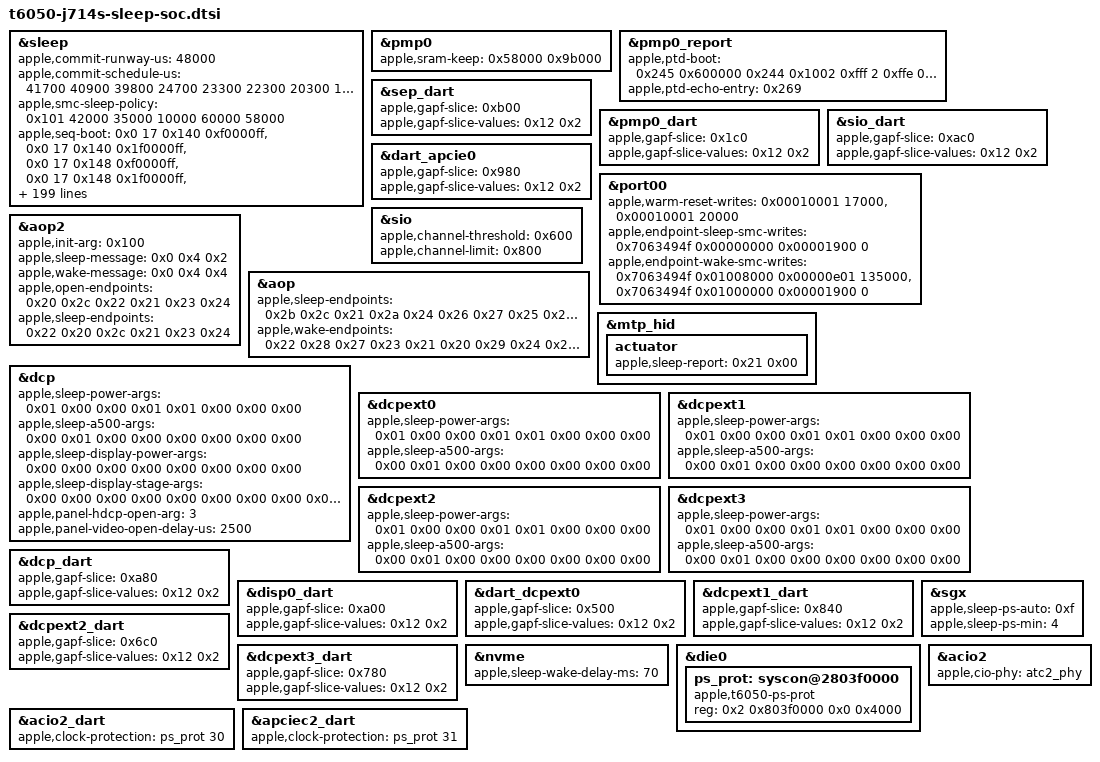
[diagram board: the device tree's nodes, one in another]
// SPDX-License-Identifier: GPL-2.0+ OR MIT
/*
 * The J714s's (MacBook Pro 14-inch, M5 Pro) SoC values for the deep sleep that the drivers take
 * from the DT, until the boot loader hands them over.
 */

&sleep {

	/* The commit window's schedule, in us before the sleep timer, step by step */
	/* The commit window: from the SMC's idle notice to the timer */
	apple,commit-runway-us = <48000>;
	apple,commit-schedule-us = <41700 40900 39800 24700 23300 22300 20300 18010 18000
		2491 2296 2202 1552 1468 1382 950 730 650 550 500>;
	/* pmVC, then the spacings: warning to pmVC, pmVC to SLPA, SLPA to idle, idle to timer, wake to pmVC */
	apple,smc-sleep-policy = <0x101 42000 35000 10000 60000 58000>;
	/* Boot: the power words put on auto, SPI_P and ATC3_USB_AON on, the SPMI masks */
	apple,seq-boot =
		<0x0 17 0x140 0xf0000ff>,
		<0x0 17 0x140 0x1f0000ff>,
		<0x0 17 0x148 0xf0000ff>,
		<0x0 17 0x148 0x1f0000ff>,
		<0x0 16 0x110 0xf0000ff>,
		<0x0 16 0x110 0x1f0000ff>,
		<0x0 16 0x168 0xf0000ff>,
		<0x0 16 0x168 0x1f0000ff>,
		<0x0 16 0x178 0xf0000ff>,
		<0x0 16 0x178 0x1f0000ff>,
		<0x0 16 0x450 0xf0000ff>,
		<0x0 16 0x450 0x1f0000ff>,
		<0x0 20 0x198 0xf0000ff>,
		<0x0 20 0x198 0x1f0000ff>,
		<0x0 20 0x130 0xf0000ff>,
		<0x0 20 0x130 0x1f0000ff>,
		<0x0 20 0x140 0xf0000ff>,
		<0x0 20 0x140 0x1f0000ff>,
		<0x0 18 0x60 0xf0000ff>,
		<0x0 18 0x60 0x1f0000ff>,
		<0x0 18 0x68 0xf0000ff>,
		<0x0 18 0x68 0x1f0000ff>,
		<0x0 18 0x128 0xf0000ff>,
		<0x0 18 0x128 0x1f0000ff>,
		<0x0 18 0x140 0xf0000ff>,
		<0x0 18 0x140 0x1f0000ff>,
		<0x0 18 0x58 0xf0000ff>,
		<0x0 18 0x58 0x1f0000ff>,
		<0x0 21 0x58 0xf0000ff>,
		<0x0 21 0x58 0x1f0000ff>,
		<0x0 16 0x148 0xf0000ff>,
		<0x0 16 0x148 0x1f0000ff>,
		<0x0 16 0x150 0xf0000ff>,
		<0x0 16 0x150 0x1f0000ff>,
		<0x0 16 0x158 0xf0000ff>,
		<0x0 16 0x158 0x1f0000ff>,
		<0x0 16 0x160 0xf0000ff>,
		<0x0 16 0x160 0x1f0000ff>,
		<0x0 16 0x1e8 0xf0000ff>,
		<0x0 16 0x1e8 0x1f0000ff>,
		<0x0 16 0x1f0 0xf0000ff>,
		<0x0 16 0x1f0 0x1f0000ff>,
		<0x0 17 0x138 0xf0000ff>,
		<0x0 17 0x138 0x1f0000ff>,
		<0x0 17 0x178 0xf0000ff>,
		<0x0 17 0x178 0x1f0000ff>,
		<0x0 17 0x288 0xf0000ff>,
		<0x0 17 0x288 0x1f0000ff>,
		<0x0 17 0x398 0xf0000ff>,
		<0x0 17 0x398 0x1f0000ff>,
		<0x0 20 0x1a8 0xf0000ff>,
		<0x0 20 0x1a8 0x1f0000ff>,
		<0x0 20 0x1b0 0xf0000ff>,
		<0x0 20 0x1b0 0x1f0000ff>,
		<0x0 20 0x218 0xf0000ff>,
		<0x0 20 0x218 0x1f0000ff>,
		<0x0 20 0x220 0xf0000ff>,
		<0x0 20 0x220 0x1f0000ff>,
		<0x0 20 0x228 0xf0000ff>,
		<0x0 20 0x228 0x1f0000ff>,
		<0x0 20 0x230 0xf0000ff>,
		<0x0 20 0x230 0x1f0000ff>,
		<0x0 20 0x238 0xf0000ff>,
		<0x0 20 0x238 0x1f0000ff>,
		<0x0 20 0x240 0xf0000ff>,
		<0x0 20 0x240 0x1f0000ff>,
		<0x0 20 0x288 0xf0000ff>,
		<0x0 20 0x288 0x1f0000ff>,
		<0x0 20 0x298 0xf0000ff>,
		<0x0 20 0x298 0x1f0000ff>,
		<0x0 20 0x2a0 0xf0000ff>,
		<0x0 20 0x2a0 0x1f0000ff>,
		<0x0 20 0x2a8 0xf0000ff>,
		<0x0 20 0x2a8 0x1f0000ff>,
		<0x0 20 0x2b0 0xf0000ff>,
		<0x0 20 0x2b0 0x1f0000ff>,
		<0x0 20 0x2b8 0xf0000ff>,
		<0x0 20 0x2b8 0x1f0000ff>,
		<0x0 20 0x2c0 0xf0000ff>,
		<0x0 20 0x2c0 0x1f0000ff>,
		<0x0 20 0x308 0xf0000ff>,
		<0x0 20 0x308 0x1f0000ff>,
		<0x0 20 0x318 0xf0000ff>,
		<0x0 20 0x318 0x1f0000ff>,
		<0x0 20 0x320 0xf0000ff>,
		<0x0 20 0x320 0x1f0000ff>,
		<0x0 20 0x328 0xf0000ff>,
		<0x0 20 0x328 0x1f0000ff>,
		<0x0 20 0x330 0xf0000ff>,
		<0x0 20 0x330 0x1f0000ff>,
		<0x0 20 0x338 0xf0000ff>,
		<0x0 20 0x338 0x1f0000ff>,
		<0x0 20 0x340 0xf0000ff>,
		<0x0 20 0x340 0x1f0000ff>,
		<0x0 20 0x388 0xf0000ff>,
		<0x0 20 0x388 0x1f0000ff>,
		<0x0 20 0x398 0xf0000ff>,
		<0x0 20 0x398 0x1f0000ff>,
		<0x0 20 0x3a0 0xf0000ff>,
		<0x0 20 0x3a0 0x1f0000ff>,
		<0x0 20 0x3a8 0xf0000ff>,
		<0x0 20 0x3a8 0x1f0000ff>,
		<0x0 20 0x3b0 0xf0000ff>,
		<0x0 20 0x3b0 0x1f0000ff>,
		<0x0 20 0x3b8 0xf0000ff>,
		<0x0 20 0x3b8 0x1f0000ff>,
		<0x0 20 0x3c0 0xf0000ff>,
		<0x0 20 0x3c0 0x1f0000ff>,
		<0x0 20 0x408 0xf0000ff>,
		<0x0 20 0x408 0x1f0000ff>,
		<0x0 17 0x308 0xff>,
		<0x0 17 0x308 0x100000ff>,
		<0x0 18 0x190 0xff>,
		<0x0 18 0x190 0x100000ff>,
		<0x0 39 0x420 0x3f833ff1>,
		<0x0 8 0x420 0x3f833ff1>,
		<0x0 9 0x420 0x3f833ff1>,
		<0x0 10 0x420 0x3f833ff1>,
		<0x0 11 0x420 0x3f833ff1>,
		<0x0 12 0x420 0x3f833ff1>,
		<0x0 12 0x41c 0x20>,
		<0x0 12 0x41c 0x28>,
		<0x0 39 0x404 0x40000000>,
		<0x0 39 0x604 0x40000000>,
		<0x0 39 0x400 0x4>;
	apple,spmi-runtime-mask = <0x3f833ff1>;
	/*
	 * nub-spmi0: the PMU's interrupt source (the one apple,seq-boot enables at 0x400),
	 * latched in 0x600 bit 2. Acknowledged at every wake before the run-time mask goes
	 * back, as macOS does.
	 */
	apple,spmi-pmu-sources = <0x600 0x4>;
	/* The stage: the PMC's rail words */
	apple,seq-stage =
		<0x0 41 0x2000 0xb>,
		<0x0 41 0x2004 0xb>,
		<0x0 41 0x2008 0xb>,
		<0x0 41 0x200c 0xb>,
		<0x0 41 0x2028 0x40a>,
		<0x0 41 0x2020 0x10000>,
		<0x0 41 0x2020 0x0>;
	/* Commit: the auxiliary watchdog */
	apple,seq-commit-wdt =
		<0x0 37 0x2c 0x20>;
	/* Commit: AFR */
	apple,seq-commit-afr =
		<0x0 19 0x100 0x1004030f>,
		<0x0 19 0x100 0x0>;
	/* Commit: SIO, SIO_CPU, then the clock muxes parked */
	apple,seq-commit-sio =
		<0x0 17 0x290 0x400024f>,
		<0x0 17 0x2a0 0x400024f>,
		<0x1 51 0xa0 0x0>,
		<0x0 51 0xa0 0x80100400>,
		<0x1 51 0xa0 0x0>,
		<0x1 51 0xa4 0x0>,
		<0x0 51 0xa4 0x80100400>,
		<0x1 51 0xa4 0x0>,
		<0x1 51 0x94 0x0>,
		<0x0 51 0x94 0x80100400>,
		<0x1 51 0x94 0x0>,
		<0x1 51 0x90 0x0>,
		<0x0 51 0x90 0x80100400>,
		<0x1 51 0x90 0x0>;
	/* The internal display's gate words at its stop */
	apple,seq-display-gate =
		<0x0 38 0x51c 0x3>,
		<0x0 38 0x540 0x0>;
	apple,ptd-sleep = <0x1e0 12 13 14 36>;
	apple,pmu-sleep-reads = <0xf801 1 0xf808 4 0xf802 1 0xf818 1 0xf819 2 0xf800 1 0xa7dc 4>;
	apple,spmi-sleep-order = <1 0 4 2 3>;
	apple,spmi-sleep-gap-us = <480>;
	apple,pmu-alarm-rearm = <0x43 0x41>;
	apple,pmu-wake-stage = <0xfe>;
	apple,complex-requests = <0xf 0x0 0x2f 0x20>;
	apple,perf-floor-steps = <2 1>;
	apple,perf-floor-step-ms = <9>;
	apple,pmc-sleep-channels = <2 3>;
	/* The codec's reset, driven low in the sleep entry */
	apple,sleep-low-pins = <139>;
	/* The clock words the entry clears */
	apple,entry-clk-words = <0x600000 0x604000 0x608000 0x608800 0x609000 0x609800
		0x60a000 0x60a800 0x60b000 0x60c000 0x700000 0x800000
		0x802000 0x900000 0xa00000 0xa08000 0xa08800 0xa09000
		0xa09800 0xa0a000 0xa0a800 0xa0b000 0xa0c000 0xa0d000
		0xa0e000 0xa0f000>;
	/* The perf words the entry zeroes */
	apple,entry-perf-words = <0xb18000 0xc08000 0xc10000 0xb10000 0xc00000 0xb00000
		0xb08000>;
	/* The wake's restore order: power words (bit 31) and register words */
	apple,wake-order = <0x80100298 0xb18000 0x80000108 0x80000118 0x80000120 0x80000128
		0x80000130 0x80000140 0x80000200 0x80000208 0x80000210 0x80000220
		0x80000228 0x80000230 0x80000238 0x80000250 0x80000258 0x80000260
		0x80000268 0x80000278 0x800002a0 0x800002b0 0x800002b8 0x800002c8
		0x800002d0 0x800002e0 0x80100118 0x80100128 0x80100130 0x80100140
		0x80100148 0x80100150 0x80100158 0x80100290 0x801002a0 0x801002e0
		0x80100300 0x80100308 0x80100310 0x80100320 0x80100328 0x80100338
		0x80100348 0x80100358 0x80100360 0x80100368 0x80100370 0x80100378
		0x80100380 0x80100388 0x80100390 0x80200080 0x80200088 0x80200098
		0x802000a0 0x802000a8 0x802000b0 0x802000b8 0x802000c0 0x802000c8
		0x802000d0 0x802000d8 0x802000e0 0x802000e8 0x802000f0 0x80200118
		0x80200148 0x80200158 0x80200160 0x80200170 0x80200178 0x80200188
		0x80200190 0x80208028 0x80208030 0x80208038 0x80208040 0x80208048
		0x80208050 0x80300100 0x80400108 0x80400110 0x80400118 0x80400128
		0x80500068 0x801003a8 0x80400120 0x80300110 0x80208058 0x80200150
		0x80200110 0x80200108 0x80200100 0x802000f8 0x80100350 0x80100340
		0x80100330 0x80100318 0x801002f8 0x801002f0 0x801002e8 0x801002d8
		0x801002d0 0x801002c8 0x801002c0 0x801002b8 0x801002a8 0x80100258
		0x80100248 0x80100240 0x801001b0 0x80100110 0x80100108 0x80100100
		0x80000138 0x600110 0x600114 0x600100 0x600130 0x600134
		0x600120 0x600150 0x600154 0x600140 0x600170 0x600174
		0x600160 0x600190 0x600194 0x600180 0x6001b0 0x6001b4
		0x6001a0 0x6001d0 0x6001d4 0x6001c0 0x6001f0 0x6001f4
		0x6001e0 0x600210 0x600214 0x600200 0x600230 0x600234
		0x600220 0x600250 0x600254 0x600240 0x600270 0x600274
		0x600260 0x600290 0x600294 0x600280 0x6002b0 0x6002b4
		0x6002a0 0x6002d0 0x6002d4 0x6002c0 0x6002f0 0x6002f4
		0x6002e0 0x600310 0x600314 0x600300 0x600330 0x600334
		0x600320 0x600350 0x600354 0x600340 0x600370 0x600374
		0x600360 0x600390 0x600394 0x600380 0x6003b0 0x6003b4
		0x6003a0 0x6003d0 0x6003d4 0x6003c0 0x6003f0 0x6003f4
		0x6003e0 0x600410 0x600414 0x600400 0x600430 0x600434
		0x600420 0x600450 0x600454 0x600440 0x600470 0x600474
		0x600460 0x600490 0x600494 0x600480 0x6004b0 0x6004b4
		0x6004a0 0x6004d0 0x6004d4 0x6004c0 0x6004f0 0x6004f4
		0x6004e0 0x600510 0x600514 0x600500 0x600530 0x600534
		0x600520 0x600550 0x600554 0x600540 0x600570 0x600574
		0x600560 0x600590 0x600594 0x600580 0x6005b0 0x6005b4
		0x6005a0 0x6005d0 0x6005d4 0x6005c0 0x6005f0 0x6005f4
		0x6005e0 0x600610 0x600614 0x600600 0x600630 0x600634
		0x600620 0x600650 0x600654 0x600640 0x600670 0x600674
		0x600660 0x600690 0x600694 0x600680 0x800110 0x800114
		0x800100 0x800130 0x800134 0x800120 0x800150 0x800154
		0x800140 0x800170 0x800174 0x800160 0x800190 0x800194
		0x800180 0x8001b0 0x8001b4 0x8001a0 0x8001d0 0x8001d4
		0x8001c0 0x8001f0 0x8001f4 0x8001e0 0x800210 0x800214
		0x800200 0x800230 0x800234 0x800220 0x800250 0x800254
		0x800240 0x800270 0x800274 0x800260 0x800290 0x800294
		0x800280 0x8002b0 0x8002b4 0x8002a0 0x8002d0 0x8002d4
		0x8002c0 0x8002f0 0x8002f4 0x8002e0 0x800310 0x800314
		0x800300 0x800330 0x800334 0x800320 0x800350 0x800354
		0x800340 0x800370 0x800374 0x800360 0x800390 0x800394
		0x800380 0x8003b0 0x8003b4 0x8003a0 0x8003d0 0x8003d4
		0x8003c0 0x8003f0 0x8003f4 0x8003e0 0x800410 0x800414
		0x800400 0x800430 0x800434 0x800420 0x800450 0x800454
		0x800440 0x800470 0x800474 0x800460 0x800490 0x800494
		0x800480 0x900110 0x900114 0x900100 0x900130 0x900134
		0x900120 0x900150 0x900154 0x900140 0x900170 0x900174
		0x900160 0xa00110 0xa00114 0xa00100 0xa00130 0xa00134
		0xa00120 0xa00150 0xa00154 0xa00140 0xa00170 0xa00174
		0xa00160 0xa00190 0xa00194 0xa00180 0xa001b0 0xa001b4
		0xa001a0 0xa001d0 0xa001d4 0xa001c0 0xa001f0 0xa001f4
		0xa001e0 0xa00210 0xa00214 0xa00200 0xa00230 0xa00234
		0xa00220 0xa00250 0xa00254 0xa00240 0xa00270 0xa00274
		0xa00260 0xa00290 0xa00294 0xa00280 0xa002b0 0xa002b4
		0xa002a0 0xa002d0 0xa002d4 0xa002c0 0xa002f0 0xa002f4
		0xa002e0 0xa00310 0xa00314 0xa00300 0xa00330 0xa00334
		0xa00320 0xa00350 0xa00354 0xa00340 0xa00370 0xa00374
		0xa00360 0xa00390 0xa00394 0xa00380 0xa003b0 0xa003b4
		0xa003a0 0xa003d0 0xa003d4 0xa003c0 0xa003f0 0xa003f4
		0xa003e0 0xa00410 0xa00414 0xa00400 0xa00430 0xa00434
		0xa00420 0xa00450 0xa00454 0xa00440 0xa00470 0xa00474
		0xa00460 0xa00490 0xa00494 0xa00480 0xa004b0 0xa004b4
		0xa004a0 0xa004d0 0xa004d4 0xa004c0 0xa004f0 0xa004f4
		0xa004e0 0xa00510 0xa00514 0xa00500 0xa00530 0xa00534
		0xa00520 0xa00550 0xa00554 0xa00540 0xa00570 0xa00574
		0xa00560 0xa00590 0xa00594 0xa00580 0xa005b0 0xa005b4
		0xa005a0 0xa005d0 0xa005d4 0xa005c0 0xa005f0 0xa005f4
		0xa005e0 0xa00610 0xa00614 0xa00600 0xa00630 0xa00634
		0xa00620 0xa00650 0xa00654 0xa00640 0xa00670 0xa00674
		0xa00660 0xa00690 0xa00694 0xa00680 0xa006b0 0xa006b4
		0xa006a0 0xa006d0 0xa006d4 0xa006c0 0xa006f0 0xa006f4
		0xa006e0 0xa00710 0xa00714 0xa00700 0xa00730 0xa00734
		0xa00720 0xa00750 0xa00754 0xa00740 0xa00770 0xa00774
		0xa00760 0xa00790 0xa00794 0xa00780 0xa007b0 0xa007b4
		0xa007a0 0xa007d0 0xa007d4 0xa007c0 0xa007f0 0xa007f4
		0xa007e0 0xa00810 0xa00814 0xa00800 0xa00830 0xa00834
		0xa00820 0xa00850 0xa00854 0xa00840 0xa00870 0xa00874
		0xa00860 0xa00890 0xa00894 0xa00880 0xa008b0 0xa008b4
		0xa008a0 0xa008d0 0xa008d4 0xa008c0 0xa008f0 0xa008f4
		0xa008e0 0xa00910 0xa00914 0xa00900 0xa00930 0xa00934
		0xa00920 0xa00950 0xa00954 0xa00940 0xa00970 0xa00974
		0xa00960 0xa00990 0xa00994 0xa00980 0xa009b0 0xa009b4
		0xa009a0 0xa009d0 0xa009d4 0xa009c0 0xa009f0 0xa009f4
		0xa009e0 0xa00a10 0xa00a14 0xa00a00 0xa00a30 0xa00a34
		0xa00a20 0xa00a50 0xa00a54 0xa00a40 0xa00a70 0xa00a74
		0xa00a60 0xa00a90 0xa00a94 0xa00a80 0xa00ab0 0xa00ab4
		0xa00aa0 0xa00ad0 0xa00ad4 0xa00ac0 0xa00af0 0xa00af4
		0xa00ae0 0xa00b10 0xa00b14 0xa00b00 0xa00b30 0xa00b34
		0xa00b20 0xa00b50 0xa00b54 0xa00b40 0xa00b70 0xa00b74
		0xa00b60 0xa00b90 0xa00b94 0xa00b80 0xa00bb0 0xa00bb4
		0xa00ba0 0xa00bd0 0xa00bd4 0xa00bc0 0xa00bf0 0xa00bf4
		0xa00be0 0xa00c10 0xa00c14 0xa00c00 0xa00c30 0xa00c34
		0xa00c20 0xa00c50 0xa00c54 0xa00c40 0xa00c70 0xa00c74
		0xa00c60 0xa00c90 0xa00c94 0xa00c80 0xa00cb0 0xa00cb4
		0xa00ca0 0xa00cd0 0xa00cd4 0xa00cc0 0xa00cf0 0xa00cf4
		0xa00ce0 0xa00d10 0xa00d14 0xa00d00 0xa00d30 0xa00d34
		0xa00d20 0xa00d50 0xa00d54 0xa00d40 0xa00d70 0xa00d74
		0xa00d60 0xa00d90 0xa00d94 0xa00d80 0xa00db0 0xa00db4
		0xa00da0 0xa00dd0 0xa00dd4 0xa00dc0 0xa00df0 0xa00df4
		0xa00de0 0xa00e10 0xa00e14 0xa00e00 0xa00e30 0xa00e34
		0xa00e20 0xa00e50 0xa00e54 0xa00e40 0xa00e70 0xa00e74
		0xa00e60 0xa00e90 0xa00e94 0xa00e80 0xa00eb0 0xa00eb4
		0xa00ea0 0xa00ed0 0xa00ed4 0xa00ec0 0xa00ef0 0xa00ef4
		0xa00ee0 0xa00f10 0xa00f14 0xa00f00 0xa00f30 0xa00f34
		0xa00f20 0xa00f50 0xa00f54 0xa00f40 0xa00f70 0xa00f74
		0xa00f60 0xa00f90 0xa00f94 0xa00f80 0xa00fb0 0xa00fb4
		0xa00fa0 0xa00fd0 0xa00fd4 0xa00fc0 0xa00ff0 0xa00ff4
		0xa00fe0 0xa01010 0xa01014 0xa01000 0xa01030 0xa01034
		0xa01020 0xa01050 0xa01054 0xa01040 0xa01070 0xa01074
		0xa01060 0xa01090 0xa01094 0xa01080 0xa010b0 0xa010b4
		0xa010a0 0xa010d0 0xa010d4 0xa010c0 0xa010f0 0xa010f4
		0xa010e0 0xa01110 0xa01114 0xa01100 0xa01130 0xa01134
		0xa01120 0xa01150 0xa01154 0xa01140 0xa01170 0xa01174
		0xa01160 0x6006b0 0x6006b4 0x6006a0 0x6006d0 0x6006d4
		0x6006c0 0x6006f0 0x6006f4 0x6006e0 0x600710 0x600714
		0x600700 0x600730 0x600734 0x600720 0x600750 0x600754
		0x600740 0x600770 0x600774 0x600760 0x600790 0x600794
		0x600780 0x6007b0 0x6007b4 0x6007a0 0x6007d0 0x6007d4
		0x6007c0 0x8004b0 0x8004b4 0x8004a0 0x8004d0 0x8004d4
		0x8004c0 0x8004f0 0x8004f4 0x8004e0 0x800510 0x800514
		0x800500 0x800530 0x800534 0x800520 0x800550 0x800554
		0x800540 0x800570 0x800574 0x800560 0x800590 0x800594
		0x800580 0x900190 0x900194 0x900180 0x9001b0 0x9001b4
		0x9001a0 0x9001d0 0x9001d4 0x9001c0 0x9001f0 0x9001f4
		0x9001e0 0x900210 0x900214 0x900200 0x900230 0x900234
		0x900220 0x900250 0x900254 0x900240 0x900270 0x900274
		0x900260 0x900290 0x900294 0x900280 0xa01190 0xa01194
		0xa01180 0xa011b0 0xa011b4 0xa011a0 0xa011d0 0xa011d4
		0xa011c0 0xa011f0 0xa011f4 0xa011e0 0xa01210 0xa01214
		0xa01200 0xa01230 0xa01234 0xa01220 0xa01250 0xa01254
		0xa01240 0xa01270 0xa01274 0xa01260 0xa01290 0xa01294
		0xa01280 0xa012b0 0xa012b4 0xa012a0 0xa012d0 0xa012d4
		0xa012c0 0xa012f0 0xa012f4 0xa012e0 0xa01310 0xa01314
		0xa01300 0xa01330 0xa01334 0xa01320 0xa01350 0xa01354
		0xa01340 0xa01370 0xa01374 0xa01360 0x6007f0 0x6007f4
		0x6007e0 0x600810 0x600814 0x600800 0x600830 0x600834
		0x600820 0x600850 0x600854 0x600840 0x600870 0x600874
		0x600860 0x600890 0x600894 0x600880 0x6008b0 0x6008b4
		0x6008a0 0x6008d0 0x6008d4 0x6008c0 0x6008f0 0x6008f4
		0x6008e0 0x600910 0x600914 0x600900 0x600930 0x600934
		0x600920 0x600950 0x600954 0x600940 0x600970 0x600974
		0x600960 0x600990 0x600994 0x600980 0x6009b0 0x6009b4
		0x6009a0 0x6009d0 0x6009d4 0x6009c0 0x6009f0 0x6009f4
		0x6009e0 0x600a10 0x600a14 0x600a00 0x600a30 0x600a34
		0x600a20 0x600a50 0x600a54 0x600a40 0x600a70 0x600a74
		0x600a60 0x600a90 0x600a94 0x600a80 0x600ab0 0x600ab4
		0x600aa0 0x600ad0 0x600ad4 0x600ac0 0x600af0 0x600af4
		0x600ae0 0x600b10 0x600b14 0x600b00 0x600b30 0x600b34
		0x600b20 0x600b50 0x600b54 0x600b40 0x8005b0 0x8005b4
		0x8005a0 0x8005d0 0x8005d4 0x8005c0 0x8005f0 0x8005f4
		0x8005e0 0x800610 0x800614 0x800600 0x800630 0x800634
		0x800620 0x800650 0x800654 0x800640 0x800670 0x800674
		0x800660 0x800690 0x800694 0x800680 0x8006b0 0x8006b4
		0x8006a0 0x8006d0 0x8006d4 0x8006c0 0x8006f0 0x8006f4
		0x8006e0 0x800710 0x800714 0x800700 0x800730 0x800734
		0x800720 0x800750 0x800754 0x800740 0x800770 0x800774
		0x800760 0x800790 0x800794 0x800780 0x8007b0 0x8007b4
		0x8007a0 0x8007d0 0x8007d4 0x8007c0 0x8007f0 0x8007f4
		0x8007e0 0x800810 0x800814 0x800800 0x800830 0x800834
		0x800820 0x800850 0x800854 0x800840 0x800870 0x800874
		0x800860 0x800890 0x800894 0x800880 0x8008b0 0x8008b4
		0x8008a0 0x9002b0 0x9002b4 0x9002a0 0x9002d0 0x9002d4
		0x9002c0 0x9002f0 0x9002f4 0x9002e0 0x900310 0x900314
		0x900300 0xa01390 0xa01394 0xa01380 0xa013b0 0xa013b4
		0xa013a0 0xa013d0 0xa013d4 0xa013c0 0xa013f0 0xa013f4
		0xa013e0 0xa01410 0xa01414 0xa01400 0xa01430 0xa01434
		0xa01420 0xa01450 0xa01454 0xa01440 0xa01470 0xa01474
		0xa01460 0xa01490 0xa01494 0xa01480 0xa014b0 0xa014b4
		0xa014a0 0xa014d0 0xa014d4 0xa014c0 0xa014f0 0xa014f4
		0xa014e0 0xa01510 0xa01514 0xa01500 0xa01530 0xa01534
		0xa01520 0xa01550 0xa01554 0xa01540 0xa01570 0xa01574
		0xa01560 0xa01590 0xa01594 0xa01580 0xa015b0 0xa015b4
		0xa015a0 0xa015d0 0xa015d4 0xa015c0 0xa015f0 0xa015f4
		0xa015e0 0xa01610 0xa01614 0xa01600 0xa01630 0xa01634
		0xa01620 0xa01650 0xa01654 0xa01640 0xa01670 0xa01674
		0xa01660 0xa01690 0xa01694 0xa01680 0xa016b0 0xa016b4
		0xa016a0 0xa016d0 0xa016d4 0xa016c0 0xa016f0 0xa016f4
		0xa016e0 0xa01710 0xa01714 0xa01700 0xa01730 0xa01734
		0xa01720 0xa01750 0xa01754 0xa01740 0xa01770 0xa01774
		0xa01760 0xa01790 0xa01794 0xa01780 0xa017b0 0xa017b4
		0xa017a0 0xa017d0 0xa017d4 0xa017c0 0xa017f0 0xa017f4
		0xa017e0 0xa01810 0xa01814 0xa01800 0xa01830 0xa01834
		0xa01820 0xa01850 0xa01854 0xa01840 0xa01870 0xa01874
		0xa01860 0xa01890 0xa01894 0xa01880 0xa018b0 0xa018b4
		0xa018a0 0xa018d0 0xa018d4 0xa018c0 0xa018f0 0xa018f4
		0xa018e0 0xa01910 0xa01914 0xa01900 0xa01930 0xa01934
		0xa01920 0xa01950 0xa01954 0xa01940 0xa01970 0xa01974
		0xa01960 0xa01990 0xa01994 0xa01980 0xa019b0 0xa019b4
		0xa019a0 0xa019d0 0xa019d4 0xa019c0 0xa019f0 0xa019f4
		0xa019e0 0xa01a10 0xa01a14 0xa01a00 0xa01a30 0xa01a34
		0xa01a20 0xa01a50 0xa01a54 0xa01a40 0xa01a70 0xa01a74
		0xa01a60 0xa01a90 0xa01a94 0xa01a80 0xa01ab0 0xa01ab4
		0xa01aa0 0xa01ad0 0xa01ad4 0xa01ac0 0xa01af0 0xa01af4
		0xa01ae0 0xa01b10 0xa01b14 0xa01b00 0xa01b30 0xa01b34
		0xa01b20 0xa01b50 0xa01b54 0xa01b40 0x600b70 0x600b74
		0x600b90 0x600b94 0x600b60 0x600b80 0x600bb0 0x600bb4
		0x600bd0 0x600bd4 0x600ba0 0x600bc0 0x600bf0 0x600bf4
		0x600c10 0x600c14 0x600be0 0x600c00 0x600c30 0x600c34
		0x600c50 0x600c54 0x600c20 0x600c40 0x600c70 0x600c74
		0x600c90 0x600c94 0x600c60 0x600c80 0x600cb0 0x600cb4
		0x600cd0 0x600cd4 0x600ca0 0x600cc0 0x600cf0 0x600cf4
		0x600d10 0x600d14 0x600ce0 0x600d00 0x600d30 0x600d34
		0x600d50 0x600d54 0x600d20 0x600d40 0x600d70 0x600d74
		0x600d90 0x600d94 0x600d60 0x600d80 0x600db0 0x600db4
		0x600dd0 0x600dd4 0x600da0 0x600dc0 0x600df0 0x600df4
		0x600e10 0x600e14 0x600de0 0x600e00 0x600e30 0x600e34
		0x600e50 0x600e54 0x600e20 0x600e40 0x600e70 0x600e74
		0x600e90 0x600e94 0x600e60 0x600e80 0x600eb0 0x600eb4
		0x600ed0 0x600ed4 0x600ea0 0x600ec0 0x600ef0 0x600ef4
		0x600f10 0x600f14 0x600ee0 0x600f00 0x600f30 0x600f34
		0x600f50 0x600f54 0x600f20 0x600f40 0x600f70 0x600f74
		0x600f90 0x600f94 0x600f60 0x600f80 0x600fb0 0x600fb4
		0x600fd0 0x600fd4 0x600fa0 0x600fc0 0x600ff0 0x600ff4
		0x601010 0x601014 0x600fe0 0x601000 0x601030 0x601034
		0x601050 0x601054 0x601020 0x601040 0x601070 0x601074
		0x601090 0x601094 0x601060 0x601080 0x6010b0 0x6010b4
		0x6010d0 0x6010d4 0x6010a0 0x6010c0 0x6010f0 0x6010f4
		0x601110 0x601114 0x6010e0 0x601100 0x601130 0x601134
		0x601150 0x601154 0x601120 0x601140 0x601170 0x601174
		0x601190 0x601194 0x601160 0x601180 0x6011b0 0x6011b4
		0x6011d0 0x6011d4 0x6011a0 0x6011c0 0x6011f0 0x6011f4
		0x601210 0x601214 0x6011e0 0x601200 0x601230 0x601234
		0x601250 0x601254 0x601220 0x601240 0x601270 0x601274
		0x601290 0x601294 0x601260 0x601280 0x6012b0 0x6012b4
		0x6012d0 0x6012d4 0x6012a0 0x6012c0 0x6012f0 0x6012f4
		0x601310 0x601314 0x6012e0 0x601300 0x601330 0x601334
		0x601350 0x601354 0x601320 0x601340 0x601370 0x601374
		0x601390 0x601394 0x601360 0x601380 0x6013b0 0x6013b4
		0x6013d0 0x6013d4 0x6013a0 0x6013c0 0x6013f0 0x6013f4
		0x601410 0x601414 0x6013e0 0x601400 0x601430 0x601434
		0x601450 0x601454 0x601420 0x601440 0x601470 0x601474
		0x601490 0x601494 0x601460 0x601480 0x6014b0 0x6014b4
		0x6014d0 0x6014d4 0x6014a0 0x6014c0 0x6014f0 0x6014f4
		0x601510 0x601514 0x6014e0 0x601500 0x601530 0x601534
		0x601550 0x601554 0x601520 0x601540 0x601570 0x601574
		0x601590 0x601594 0x601560 0x601580 0x6015b0 0x6015b4
		0x6015d0 0x6015d4 0x6015a0 0x6015c0 0x6015f0 0x6015f4
		0x601610 0x601614 0x6015e0 0x601600 0x601630 0x601634
		0x601650 0x601654 0x601620 0x601640 0x601670 0x601674
		0x601690 0x601694 0x601660 0x601680 0x6016b0 0x6016b4
		0x6016a0 0x6016d0 0x6016d4 0x6016c0 0x6016f0 0x6016f4
		0x6016e0 0x601710 0x601714 0x601700 0x601730 0x601734
		0x601720 0x601750 0x601754 0x601740 0x601770 0x601774
		0x601760 0x601790 0x601794 0x601780 0x6017b0 0x6017b4
		0x6017a0 0x6017d0 0x6017d4 0x6017c0 0x6017f0 0x6017f4
		0x601810 0x601814 0x6017e0 0x601800 0x601830 0x601834
		0x601850 0x601854 0x601820 0x601840 0x601870 0x601874
		0x601890 0x601894 0x601860 0x601880 0x6018b0 0x6018b4
		0x6018d0 0x6018d4 0x6018a0 0x6018c0 0x6018f0 0x6018f4
		0x601910 0x601914 0x6018e0 0x601900 0x601930 0x601934
		0x601950 0x601954 0x601920 0x601940 0x601970 0x601974
		0x601990 0x601994 0x601960 0x601980 0x6019b0 0x6019b4
		0x6019d0 0x6019d4 0x6019a0 0x6019c0 0x6019f0 0x6019f4
		0x601a10 0x601a14 0x6019e0 0x601a00 0x601a30 0x601a34
		0x601a50 0x601a54 0x601a20 0x601a40 0x601a70 0x601a74
		0x601a60 0x601a90 0x601a94 0x601a80 0x601ab0 0x601ab4
		0x601aa0 0x601ad0 0x601ad4 0x601ac0 0x601af0 0x601af4
		0x601ae0 0x601b10 0x601b14 0x601b00 0x601b30 0x601b34
		0x601b20 0x601b50 0x601b54 0x601b40 0x601b70 0x601b74
		0x601b60 0x601b90 0x601b94 0x601b80 0x601bb0 0x601bb4
		0x601bd0 0x601bd4 0x601ba0 0x601bc0 0x601bf0 0x601bf4
		0x601c10 0x601c14 0x601be0 0x601c00 0x601c30 0x601c34
		0x601c20 0x601c50 0x601c54 0x601c40 0x601c70 0x601c74
		0x601c60 0x601cb0 0x601cb4 0x601c90 0x601c94 0x601ca0
		0x601c80 0x601cf0 0x601cf4 0x601cd0 0x601cd4 0x601ce0
		0x601cc0 0x601d30 0x601d34 0x601d10 0x601d14 0x601d20
		0x601d00 0x601d70 0x601d74 0x601d50 0x601d54 0x601d60
		0x601d40 0x601db0 0x601db4 0x601d90 0x601d94 0x601da0
		0x601d80 0x601df0 0x601df4 0x601dd0 0x601dd4 0x601de0
		0x601dc0 0x601e30 0x601e34 0x601e10 0x601e14 0x601e20
		0x601e00 0x601e70 0x601e74 0x601e50 0x601e54 0x601e60
		0x601e40 0x601eb0 0x601eb4 0x601e90 0x601e94 0x601ea0
		0x601e80 0x601ef0 0x601ef4 0x601ed0 0x601ed4 0x601ee0
		0x601ec0 0x601f30 0x601f34 0x601f10 0x601f14 0x601f20
		0x601f00 0x601f70 0x601f74 0x601f50 0x601f54 0x601f60
		0x601f40 0x601fb0 0x601fb4 0x601f90 0x601f94 0x601fa0
		0x601f80 0x601ff0 0x601ff4 0x601fd0 0x601fd4 0x601fe0
		0x601fc0 0x602030 0x602034 0x602010 0x602014 0x602020
		0x602000 0x602070 0x602074 0x602050 0x602054 0x602060
		0x602040 0x6020b0 0x6020b4 0x602090 0x602094 0x6020a0
		0x602080 0x6020f0 0x6020f4 0x6020d0 0x6020d4 0x6020e0
		0x6020c0 0x602130 0x602134 0x602110 0x602114 0x602120
		0x602100 0x602170 0x602174 0x602150 0x602154 0x602160
		0x602140 0x6021b0 0x6021b4 0x602190 0x602194 0x6021a0
		0x602180 0x6021f0 0x6021f4 0x6021d0 0x6021d4 0x6021e0
		0x6021c0 0x602230 0x602234 0x602210 0x602214 0x602220
		0x602200 0x602270 0x602274 0x602250 0x602254 0x602260
		0x602240 0x6022b0 0x6022b4 0x602290 0x602294 0x6022a0
		0x602280 0x6022f0 0x6022f4 0x6022d0 0x6022d4 0x6022e0
		0x6022c0 0x602330 0x602334 0x602310 0x602314 0x602320
		0x602300 0x602370 0x602374 0x602350 0x602354 0x602360
		0x602340 0x6023b0 0x6023b4 0x602390 0x602394 0x6023a0
		0x602380 0x6023f0 0x6023f4 0x6023d0 0x6023d4 0x6023e0
		0x6023c0 0x602430 0x602434 0x602410 0x602414 0x602420
		0x602400 0x602470 0x602474 0x602450 0x602454 0x602460
		0x602440 0x602490 0x602494 0x602480 0x6024b0 0x6024b4
		0x6024a0 0x6024d0 0x6024d4 0x6024c0 0x6024f0 0x6024f4
		0x6024e0 0x602510 0x602514 0x602500 0x602530 0x602534
		0x602520 0x602550 0x602554 0x602540 0x602570 0x602574
		0x602560 0x602590 0x602594 0x602580 0x6025b0 0x6025b4
		0x6025a0 0x6025d0 0x6025d4 0x6025c0 0x6025f0 0x6025f4
		0x6025e0 0x602610 0x602614 0x602600 0x602630 0x602634
		0x602620 0x602650 0x602654 0x602640 0x602670 0x602674
		0x602660 0x602690 0x602694 0x6026b0 0x6026b4 0x602680
		0x6026a0 0x6026d0 0x6026d4 0x6026f0 0x6026f4 0x6026c0
		0x6026e0 0x602710 0x602714 0x602730 0x602734 0x602700
		0x602720 0x602750 0x602754 0x602770 0x602774 0x602740
		0x602760 0x602790 0x602794 0x6027b0 0x6027b4 0x602780
		0x6027a0 0x6027d0 0x6027d4 0x6027f0 0x6027f4 0x6027c0
		0x6027e0 0x602810 0x602814 0x602830 0x602834 0x602800
		0x602820 0x602850 0x602854 0x602870 0x602874 0x602840
		0x602860 0x602890 0x602894 0x6028b0 0x6028b4 0x602880
		0x6028a0 0x6028d0 0x6028d4 0x6028f0 0x6028f4 0x6028c0
		0x6028e0 0x602910 0x602914 0x602900 0x602930 0x602934
		0x602920 0x602950 0x602954 0x602940 0x602970 0x602974
		0x602960 0x602990 0x602994 0x602980 0x6029b0 0x6029b4
		0x6029a0 0x6029d0 0x6029d4 0x6029c0 0x6029f0 0x6029f4
		0x6029e0 0x602a10 0x602a14 0x602a00 0x602a30 0x602a34
		0x602a20 0x602a50 0x602a54 0x602a40 0x604110 0x604114
		0x604130 0x604134 0x604100 0x604120 0x604150 0x604154
		0x604170 0x604174 0x604140 0x604160 0x604190 0x604194
		0x6041b0 0x6041b4 0x604180 0x6041a0 0x6041d0 0x6041d4
		0x6041f0 0x6041f4 0x6041c0 0x6041e0 0x604210 0x604214
		0x604230 0x604234 0x604200 0x604220 0x604250 0x604254
		0x604270 0x604274 0x604240 0x604260 0x604290 0x604294
		0x6042b0 0x6042b4 0x604280 0x6042a0 0x6042d0 0x6042d4
		0x6042f0 0x6042f4 0x6042c0 0x6042e0 0x604310 0x604314
		0x604330 0x604334 0x604300 0x604320 0x608110 0x608114
		0x608130 0x608134 0x608100 0x608120 0x608150 0x608154
		0x608170 0x608174 0x608140 0x608160 0x608190 0x608194
		0x6081b0 0x6081b4 0x608180 0x6081a0 0x6081d0 0x6081d4
		0x6081f0 0x6081f4 0x6081c0 0x6081e0 0x608210 0x608214
		0x608230 0x608234 0x608200 0x608220 0x608250 0x608254
		0x608270 0x608274 0x608240 0x608260 0x608290 0x608294
		0x6082b0 0x6082b4 0x608280 0x6082a0 0x6082d0 0x6082d4
		0x6082f0 0x6082f4 0x6082c0 0x6082e0 0x608310 0x608314
		0x608330 0x608334 0x608300 0x608320 0x608910 0x608914
		0x608930 0x608934 0x608900 0x608920 0x608950 0x608954
		0x608970 0x608974 0x608940 0x608960 0x608990 0x608994
		0x6089b0 0x6089b4 0x608980 0x6089a0 0x6089d0 0x6089d4
		0x6089f0 0x6089f4 0x6089c0 0x6089e0 0x608a10 0x608a14
		0x608a30 0x608a34 0x608a00 0x608a20 0x608a50 0x608a54
		0x608a70 0x608a74 0x608a40 0x608a60 0x608a90 0x608a94
		0x608ab0 0x608ab4 0x608a80 0x608aa0 0x608ad0 0x608ad4
		0x608af0 0x608af4 0x608ac0 0x608ae0 0x608b10 0x608b14
		0x608b30 0x608b34 0x608b00 0x608b20 0x609110 0x609114
		0x609130 0x609134 0x609100 0x609120 0x609150 0x609154
		0x609170 0x609174 0x609140 0x609160 0x609190 0x609194
		0x6091b0 0x6091b4 0x609180 0x6091a0 0x6091d0 0x6091d4
		0x6091f0 0x6091f4 0x6091c0 0x6091e0 0x609210 0x609214
		0x609230 0x609234 0x609200 0x609220 0x609250 0x609254
		0x609270 0x609274 0x609240 0x609260 0x609290 0x609294
		0x6092b0 0x6092b4 0x609280 0x6092a0 0x6092d0 0x6092d4
		0x6092f0 0x6092f4 0x6092c0 0x6092e0 0x609310 0x609314
		0x609330 0x609334 0x609300 0x609320 0x609910 0x609914
		0x609930 0x609934 0x609900 0x609920 0x609950 0x609954
		0x609970 0x609974 0x609940 0x609960 0x609990 0x609994
		0x6099b0 0x6099b4 0x609980 0x6099a0 0x6099d0 0x6099d4
		0x6099f0 0x6099f4 0x6099c0 0x6099e0 0x609a10 0x609a14
		0x609a30 0x609a34 0x609a00 0x609a20 0x609a50 0x609a54
		0x609a70 0x609a74 0x609a40 0x609a60 0x609a90 0x609a94
		0x609ab0 0x609ab4 0x609a80 0x609aa0 0x609ad0 0x609ad4
		0x609af0 0x609af4 0x609ac0 0x609ae0 0x609b10 0x609b14
		0x609b30 0x609b34 0x609b00 0x609b20 0x60a110 0x60a114
		0x60a130 0x60a134 0x60a100 0x60a120 0x60a150 0x60a154
		0x60a170 0x60a174 0x60a140 0x60a160 0x60a190 0x60a194
		0x60a1b0 0x60a1b4 0x60a180 0x60a1a0 0x60a1d0 0x60a1d4
		0x60a1f0 0x60a1f4 0x60a1c0 0x60a1e0 0x60a210 0x60a214
		0x60a230 0x60a234 0x60a200 0x60a220 0x60a250 0x60a254
		0x60a270 0x60a274 0x60a240 0x60a260 0x60a290 0x60a294
		0x60a2b0 0x60a2b4 0x60a280 0x60a2a0 0x60a2d0 0x60a2d4
		0x60a2f0 0x60a2f4 0x60a2c0 0x60a2e0 0x60a310 0x60a314
		0x60a330 0x60a334 0x60a300 0x60a320 0x60a910 0x60a914
		0x60a930 0x60a934 0x60a900 0x60a920 0x60a950 0x60a954
		0x60a970 0x60a974 0x60a940 0x60a960 0x60a990 0x60a994
		0x60a9b0 0x60a9b4 0x60a980 0x60a9a0 0x60a9d0 0x60a9d4
		0x60a9f0 0x60a9f4 0x60a9c0 0x60a9e0 0x60aa10 0x60aa14
		0x60aa30 0x60aa34 0x60aa00 0x60aa20 0x60aa50 0x60aa54
		0x60aa70 0x60aa74 0x60aa40 0x60aa60 0x60aa90 0x60aa94
		0x60aab0 0x60aab4 0x60aa80 0x60aaa0 0x60aad0 0x60aad4
		0x60aaf0 0x60aaf4 0x60aac0 0x60aae0 0x60ab10 0x60ab14
		0x60ab30 0x60ab34 0x60ab00 0x60ab20 0x60b110 0x60b114
		0x60b130 0x60b134 0x60b100 0x60b120 0x60b150 0x60b154
		0x60b170 0x60b174 0x60b140 0x60b160 0x60b190 0x60b194
		0x60b1b0 0x60b1b4 0x60b180 0x60b1a0 0x60b1d0 0x60b1d4
		0x60b1f0 0x60b1f4 0x60b1c0 0x60b1e0 0x60b210 0x60b214
		0x60b230 0x60b234 0x60b200 0x60b220 0x60b250 0x60b254
		0x60b270 0x60b274 0x60b240 0x60b260 0x60b290 0x60b294
		0x60b2b0 0x60b2b4 0x60b280 0x60b2a0 0x60b2d0 0x60b2d4
		0x60b2f0 0x60b2f4 0x60b2c0 0x60b2e0 0x60b310 0x60b314
		0x60b330 0x60b334 0x60b300 0x60b320 0x60c110 0x60c114
		0x60c100 0x60c130 0x60c134 0x60c120 0x60c150 0x60c154
		0x60c140 0x60c170 0x60c174 0x60c160 0x60c190 0x60c194
		0x60c180 0x60c1b0 0x60c1b4 0x60c1a0 0x60c1d0 0x60c1d4
		0x60c1c0 0x60c1f0 0x60c1f4 0x60c1e0 0x60c210 0x60c214
		0x60c200 0x60c230 0x60c234 0x60c220 0x60c250 0x60c254
		0x60c240 0x60c270 0x60c274 0x60c260 0x60c290 0x60c294
		0x60c280 0x60c2b0 0x60c2b4 0x60c2a0 0x60c2d0 0x60c2d4
		0x60c2c0 0x60c2f0 0x60c2f4 0x60c2e0 0x60c310 0x60c314
		0x60c300 0x60c330 0x60c334 0x60c320 0x60c350 0x60c354
		0x60c340 0x60c370 0x60c374 0x60c360 0x60c390 0x60c394
		0x60c380 0x60c3b0 0x60c3b4 0x60c3a0 0x60c3d0 0x60c3d4
		0x60c3c0 0x60c3f0 0x60c3f4 0x60c3e0 0x60c410 0x60c414
		0x60c400 0x60c430 0x60c434 0x60c420 0x60c450 0x60c454
		0x60c440 0x60c470 0x60c474 0x60c460 0x60c490 0x60c494
		0x60c480 0x60c4b0 0x60c4b4 0x60c4a0 0x60c4d0 0x60c4d4
		0x60c4c0 0x60c4f0 0x60c4f4 0x60c4e0 0x60c510 0x60c514
		0x60c500 0x60c530 0x60c534 0x60c520 0x60c550 0x60c554
		0x60c540 0x60c570 0x60c574 0x60c560 0x60c590 0x60c594
		0x60c580 0x60c5b0 0x60c5b4 0x60c5a0 0x60c5d0 0x60c5d4
		0x60c5c0 0x60c5f0 0x60c5f4 0x60c5e0 0x60c610 0x60c614
		0x60c600 0x60c630 0x60c634 0x60c620 0x60c650 0x60c654
		0x60c640 0x60c670 0x60c674 0x60c660 0x60c690 0x60c694
		0x60c680 0x60c6b0 0x60c6b4 0x60c6a0 0x60c6d0 0x60c6d4
		0x60c6c0 0x60c6f0 0x60c6f4 0x60c6e0 0x700108 0x70010c
		0x700100 0x700118 0x70011c 0x700110 0x700128 0x70012c
		0x700120 0x700138 0x70013c 0x700130 0x700148 0x70014c
		0x700140 0x700158 0x70015c 0x700150 0x700168 0x70016c
		0x700160 0x700178 0x70017c 0x700170 0x700188 0x70018c
		0x700180 0x700198 0x70019c 0x700190 0x7001a8 0x7001ac
		0x7001a0 0x802110 0x802114 0x802100 0x802130 0x802134
		0x802120 0x802150 0x802154 0x802140 0x802170 0x802174
		0x802160 0x802190 0x802194 0x802180 0x8021b0 0x8021b4
		0x8021a0 0x8021d0 0x8021d4 0x8021c0 0x8021f0 0x8021f4
		0x8021e0 0x802210 0x802214 0x802200 0x802230 0x802234
		0x802220 0x802250 0x802254 0x802240 0x802270 0x802274
		0x802260 0x802290 0x802294 0x802280 0x8022b0 0x8022b4
		0x8022a0 0x8022d0 0x8022d4 0x8022c0 0x8022f0 0x8022f4
		0x8022e0 0x802310 0x802314 0x802300 0x802330 0x802334
		0x802320 0x802350 0x802354 0x802340 0x802370 0x802374
		0x802360 0x802390 0x802394 0x802380 0x8023b0 0x8023b4
		0x8023a0 0x8023d0 0x8023d4 0x8023c0 0x8023f0 0x8023f4
		0x8023e0 0x802410 0x802414 0x802400 0x802430 0x802434
		0x802420 0x802450 0x802454 0x802440 0x802470 0x802474
		0x802460 0x802490 0x802494 0x802480 0x8024b0 0x8024b4
		0x8024a0 0x8024d0 0x8024d4 0x8024c0 0x8024f0 0x8024f4
		0x8024e0 0x802510 0x802514 0x802500 0x802530 0x802534
		0x802520 0x802550 0x802554 0x802540 0x802570 0x802574
		0x802560 0x802590 0x802594 0x802580 0xa01b70 0xa01b74
		0xa01b90 0xa01b94 0xa01b60 0xa01b80 0xa01bb0 0xa01bb4
		0xa01bd0 0xa01bd4 0xa01ba0 0xa01bc0 0xa01bf0 0xa01bf4
		0xa01c10 0xa01c14 0xa01be0 0xa01c00 0xa01c30 0xa01c34
		0xa01c50 0xa01c54 0xa01c20 0xa01c40 0xa01c70 0xa01c74
		0xa01c90 0xa01c94 0xa01c60 0xa01c80 0xa01cb0 0xa01cb4
		0xa01cd0 0xa01cd4 0xa01ca0 0xa01cc0 0xa01cf0 0xa01cf4
		0xa01d10 0xa01d14 0xa01ce0 0xa01d00 0xa01d30 0xa01d34
		0xa01d50 0xa01d54 0xa01d20 0xa01d40 0xa01d70 0xa01d74
		0xa01d90 0xa01d94 0xa01d60 0xa01d80 0xa01dd0 0xa01dd4
		0xa01db0 0xa01db4 0xa01dc0 0xa01da0 0xa01df0 0xa01df4
		0xa01e10 0xa01e14 0xa01de0 0xa01e00 0xa01e30 0xa01e34
		0xa01e50 0xa01e54 0xa01e20 0xa01e40 0xa01e70 0xa01e74
		0xa01e60 0xa01e90 0xa01e94 0xa01e80 0xa01eb0 0xa01eb4
		0xa01ea0 0xa01ed0 0xa01ed4 0xa01ec0 0xa01ef0 0xa01ef4
		0xa01ee0 0xa01f10 0xa01f14 0xa01f00 0xa01f30 0xa01f34
		0xa01f20 0xa01f50 0xa01f54 0xa01f40 0xa01f70 0xa01f74
		0xa01f60 0xa01f90 0xa01f94 0xa01f80 0xa01fb0 0xa01fb4
		0xa01fa0 0xa01fd0 0xa01fd4 0xa01fc0 0xa01ff0 0xa01ff4
		0xa01fe0 0xa02010 0xa02014 0xa02000 0xa02030 0xa02034
		0xa02020 0xa02050 0xa02054 0xa02040 0xa02070 0xa02074
		0xa02060 0xa02090 0xa02094 0xa02080 0xa020b0 0xa020b4
		0xa020a0 0xa08110 0xa08114 0xa08130 0xa08134 0xa08100
		0xa08120 0xa08150 0xa08154 0xa08170 0xa08174 0xa08140
		0xa08160 0xa08190 0xa08194 0xa081b0 0xa081b4 0xa08180
		0xa081a0 0xa081d0 0xa081d4 0xa081f0 0xa081f4 0xa081c0
		0xa081e0 0xa08210 0xa08214 0xa08230 0xa08234 0xa08200
		0xa08220 0xa08250 0xa08254 0xa08270 0xa08274 0xa08240
		0xa08260 0xa08290 0xa08294 0xa082b0 0xa082b4 0xa08280
		0xa082a0 0xa082d0 0xa082d4 0xa082f0 0xa082f4 0xa082c0
		0xa082e0 0xa08310 0xa08314 0xa08330 0xa08334 0xa08300
		0xa08320 0xa08910 0xa08914 0xa08930 0xa08934 0xa08900
		0xa08920 0xa08950 0xa08954 0xa08970 0xa08974 0xa08940
		0xa08960 0xa08990 0xa08994 0xa089b0 0xa089b4 0xa08980
		0xa089a0 0xa089d0 0xa089d4 0xa089f0 0xa089f4 0xa089c0
		0xa089e0 0xa08a10 0xa08a14 0xa08a30 0xa08a34 0xa08a00
		0xa08a20 0xa08a50 0xa08a54 0xa08a70 0xa08a74 0xa08a40
		0xa08a60 0xa08a90 0xa08a94 0xa08ab0 0xa08ab4 0xa08a80
		0xa08aa0 0xa08ad0 0xa08ad4 0xa08af0 0xa08af4 0xa08ac0
		0xa08ae0 0xa08b10 0xa08b14 0xa08b30 0xa08b34 0xa08b00
		0xa08b20 0xa09110 0xa09114 0xa09130 0xa09134 0xa09100
		0xa09120 0xa09150 0xa09154 0xa09170 0xa09174 0xa09140
		0xa09160 0xa09190 0xa09194 0xa091b0 0xa091b4 0xa09180
		0xa091a0 0xa091d0 0xa091d4 0xa091f0 0xa091f4 0xa091c0
		0xa091e0 0xa09210 0xa09214 0xa09230 0xa09234 0xa09200
		0xa09220 0xa09250 0xa09254 0xa09270 0xa09274 0xa09240
		0xa09260 0xa09290 0xa09294 0xa092b0 0xa092b4 0xa09280
		0xa092a0 0xa092d0 0xa092d4 0xa092f0 0xa092f4 0xa092c0
		0xa092e0 0xa09310 0xa09314 0xa09330 0xa09334 0xa09300
		0xa09320 0xa09910 0xa09914 0xa09930 0xa09934 0xa09900
		0xa09920 0xa09950 0xa09954 0xa09970 0xa09974 0xa09940
		0xa09960 0xa09990 0xa09994 0xa099b0 0xa099b4 0xa09980
		0xa099a0 0xa099d0 0xa099d4 0xa099f0 0xa099f4 0xa099c0
		0xa099e0 0xa09a10 0xa09a14 0xa09a30 0xa09a34 0xa09a00
		0xa09a20 0xa09a50 0xa09a54 0xa09a70 0xa09a74 0xa09a40
		0xa09a60 0xa09a90 0xa09a94 0xa09ab0 0xa09ab4 0xa09a80
		0xa09aa0 0xa09ad0 0xa09ad4 0xa09af0 0xa09af4 0xa09ac0
		0xa09ae0 0xa09b10 0xa09b14 0xa09b30 0xa09b34 0xa09b00
		0xa09b20 0xa0a110 0xa0a114 0xa0a130 0xa0a134 0xa0a100
		0xa0a120 0xa0a150 0xa0a154 0xa0a170 0xa0a174 0xa0a140
		0xa0a160 0xa0a190 0xa0a194 0xa0a1b0 0xa0a1b4 0xa0a180
		0xa0a1a0 0xa0a1d0 0xa0a1d4 0xa0a1f0 0xa0a1f4 0xa0a1c0
		0xa0a1e0 0xa0a210 0xa0a214 0xa0a230 0xa0a234 0xa0a200
		0xa0a220 0xa0a250 0xa0a254 0xa0a270 0xa0a274 0xa0a240
		0xa0a260 0xa0a290 0xa0a294 0xa0a2b0 0xa0a2b4 0xa0a280
		0xa0a2a0 0xa0a2d0 0xa0a2d4 0xa0a2f0 0xa0a2f4 0xa0a2c0
		0xa0a2e0 0xa0a310 0xa0a314 0xa0a330 0xa0a334 0xa0a300
		0xa0a320 0xa0a910 0xa0a914 0xa0a930 0xa0a934 0xa0a900
		0xa0a920 0xa0a950 0xa0a954 0xa0a970 0xa0a974 0xa0a940
		0xa0a960 0xa0a990 0xa0a994 0xa0a9b0 0xa0a9b4 0xa0a980
		0xa0a9a0 0xa0a9d0 0xa0a9d4 0xa0a9f0 0xa0a9f4 0xa0a9c0
		0xa0a9e0 0xa0aa10 0xa0aa14 0xa0aa30 0xa0aa34 0xa0aa00
		0xa0aa20 0xa0aa50 0xa0aa54 0xa0aa70 0xa0aa74 0xa0aa40
		0xa0aa60 0xa0aa90 0xa0aa94 0xa0aab0 0xa0aab4 0xa0aa80
		0xa0aaa0 0xa0aad0 0xa0aad4 0xa0aaf0 0xa0aaf4 0xa0aac0
		0xa0aae0 0xa0ab10 0xa0ab14 0xa0ab30 0xa0ab34 0xa0ab00
		0xa0ab20 0xa0b110 0xa0b114 0xa0b130 0xa0b134 0xa0b100
		0xa0b120 0xa0b150 0xa0b154 0xa0b170 0xa0b174 0xa0b140
		0xa0b160 0xa0b190 0xa0b194 0xa0b1b0 0xa0b1b4 0xa0b180
		0xa0b1a0 0xa0b1d0 0xa0b1d4 0xa0b1f0 0xa0b1f4 0xa0b1c0
		0xa0b1e0 0xa0b210 0xa0b214 0xa0b230 0xa0b234 0xa0b200
		0xa0b220 0xa0b250 0xa0b254 0xa0b270 0xa0b274 0xa0b240
		0xa0b260 0xa0b290 0xa0b294 0xa0b2b0 0xa0b2b4 0xa0b280
		0xa0b2a0 0xa0b2d0 0xa0b2d4 0xa0b2f0 0xa0b2f4 0xa0b2c0
		0xa0b2e0 0xa0b310 0xa0b314 0xa0b330 0xa0b334 0xa0b300
		0xa0b320 0xa0c110 0xa0c114 0xa0c130 0xa0c134 0xa0c100
		0xa0c120 0xa0c150 0xa0c154 0xa0c170 0xa0c174 0xa0c140
		0xa0c160 0xa0c190 0xa0c194 0xa0c1b0 0xa0c1b4 0xa0c180
		0xa0c1a0 0xa0c1d0 0xa0c1d4 0xa0c1f0 0xa0c1f4 0xa0c1c0
		0xa0c1e0 0xa0c210 0xa0c214 0xa0c230 0xa0c234 0xa0c200
		0xa0c220 0xa0c250 0xa0c254 0xa0c270 0xa0c274 0xa0c240
		0xa0c260 0xa0c290 0xa0c294 0xa0c2b0 0xa0c2b4 0xa0c280
		0xa0c2a0 0xa0c2d0 0xa0c2d4 0xa0c2f0 0xa0c2f4 0xa0c2c0
		0xa0c2e0 0xa0c310 0xa0c314 0xa0c330 0xa0c334 0xa0c300
		0xa0c320 0xa0d110 0xa0d114 0xa0d130 0xa0d134 0xa0d100
		0xa0d120 0xa0d150 0xa0d154 0xa0d170 0xa0d174 0xa0d140
		0xa0d160 0xa0d190 0xa0d194 0xa0d1b0 0xa0d1b4 0xa0d180
		0xa0d1a0 0xa0d1d0 0xa0d1d4 0xa0d1f0 0xa0d1f4 0xa0d1c0
		0xa0d1e0 0xa0d210 0xa0d214 0xa0d230 0xa0d234 0xa0d200
		0xa0d220 0xa0d250 0xa0d254 0xa0d270 0xa0d274 0xa0d240
		0xa0d260 0xa0d290 0xa0d294 0xa0d2b0 0xa0d2b4 0xa0d280
		0xa0d2a0 0xa0d2d0 0xa0d2d4 0xa0d2f0 0xa0d2f4 0xa0d2c0
		0xa0d2e0 0xa0d310 0xa0d314 0xa0d330 0xa0d334 0xa0d300
		0xa0d320 0xa0e110 0xa0e114 0xa0e130 0xa0e134 0xa0e100
		0xa0e120 0xa0e150 0xa0e154 0xa0e170 0xa0e174 0xa0e140
		0xa0e160 0xa0e190 0xa0e194 0xa0e1b0 0xa0e1b4 0xa0e180
		0xa0e1a0 0xa0e1d0 0xa0e1d4 0xa0e1f0 0xa0e1f4 0xa0e1c0
		0xa0e1e0 0xa0e210 0xa0e214 0xa0e230 0xa0e234 0xa0e200
		0xa0e220 0xa0e250 0xa0e254 0xa0e270 0xa0e274 0xa0e240
		0xa0e260 0xa0e290 0xa0e294 0xa0e2b0 0xa0e2b4 0xa0e280
		0xa0e2a0 0xa0e2d0 0xa0e2d4 0xa0e2f0 0xa0e2f4 0xa0e2c0
		0xa0e2e0 0xa0e310 0xa0e314 0xa0e330 0xa0e334 0xa0e300
		0xa0e320 0x600000 0x604000 0x608000 0x608800 0x609000
		0x609800 0x60a000 0x60a800 0x60b000 0x60c000 0x700000
		0x800000 0x802000 0x900000 0xa00000 0xa08000 0xa08800
		0xa09000 0xa09800 0xa0a000 0xa0a800 0xa0b000 0xa0c000
		0xa0d000 0xa0e000 0xa0f000 0xb00000 0xb08000 0xc00000
		0xb10000 0xc08000 0xc10000 0xd00000 0xd00044 0xd00088
		0xd000cc 0xd00110 0xd00154 0xd00198 0xd001dc 0xd00220
		0xd00264 0xd002a8 0xd002ec 0xd00330 0xd00374 0xd003b8
		0xd003fc 0xd00440 0xd00484 0xd004c8 0xd0050c 0xd00550
		0xd00594 0xd005d8 0xd0061c 0xd00660 0xd006a4 0xd006e8
		0xe00000 0xe00024 0xe00048 0xe0006c 0xe00090 0xe000b4
		0xe000d8 0xe000fc 0xe00120 0xe00144 0xe00168 0xe0018c
		0xe001b0 0xe001d4 0xe001f8 0xe0021c 0xe00240 0xe00264
		0xe00288 0xe002ac 0xe002d0 0xe002f4 0xe00318 0xe0033c
		0xe00360 0xf00000 0xf00044 0xf00088 0xf000cc 0xf00110
		0xf00154 0xf00198 0xf001dc 0xf00220 0xf00264 0xf002a8
		0xf002ec 0xf00330 0xf00374 0x80100268 0x80100270 0x80100280
		0x80100180 0x80100198 0x801001a8 0x804001c8 0x80400200 0x804001f8
		0x80400208>;
	/* The PMGR clock pages' one-time clock-gating set-up: reg index, offset, value */
	apple,clk-gating-boot =
		<28 0x100 0x4
		28 0x120 0x4
		28 0x140 0x4
		28 0x160 0x4
		28 0x180 0x4
		28 0x1a0 0x4
		28 0x1c0 0x4
		28 0x1e0 0x4
		28 0x200 0x4
		28 0x220 0x4
		28 0x240 0x4
		28 0x260 0x4
		28 0x280 0x4
		28 0x2a0 0x4
		28 0x2c0 0x4
		28 0x2e0 0x4
		28 0x300 0x4
		28 0x320 0x4
		28 0x340 0x4
		28 0x360 0x4
		28 0x380 0x4
		28 0x3a0 0x4
		28 0x3c0 0x4
		28 0x3e0 0x4
		28 0x400 0x4
		28 0x420 0x4
		28 0x440 0x4
		28 0x460 0x4
		28 0x480 0x4
		28 0x4a0 0x4
		28 0x4c0 0x4
		28 0x4e0 0x4
		28 0x500 0x4
		28 0x520 0x4
		28 0x540 0x4
		28 0x560 0x4
		28 0x580 0x4
		28 0x5a0 0x4
		28 0x5c0 0x4
		28 0x5e0 0x4
		28 0x600 0x4
		28 0x620 0x4
		28 0x640 0x4
		28 0x660 0x4
		29 0x100 0x4
		29 0x120 0x4
		29 0x140 0x4
		29 0x160 0x4
		29 0x180 0x4
		28 0x680 0x4
		28 0x6a0 0x4
		28 0x6c0 0x4
		28 0x6e0 0x4
		28 0x700 0x4
		28 0x720 0x4
		28 0x740 0x4
		28 0x760 0x4
		28 0x780 0x4
		28 0x7a0 0x4
		28 0xac0 0x4
		28 0xae0 0x4
		29 0x1a0 0x4
		29 0x1c0 0x4
		29 0x1e0 0x4
		29 0x200 0x4
		29 0x220 0x4
		29 0x240 0x4
		29 0x3c0 0x4
		29 0x3e0 0x4
		28 0x7c0 0x4
		28 0x7e0 0x4
		28 0x800 0x4
		28 0x820 0x4
		28 0x840 0x4
		28 0x860 0x4
		28 0x880 0x4
		28 0x8a0 0x4
		28 0x8c0 0x4
		28 0x8e0 0x4
		29 0x260 0x4
		29 0x280 0x4
		29 0x2a0 0x4
		28 0x900 0x4
		28 0x920 0x5
		28 0x940 0x4
		28 0x960 0x5
		28 0x980 0x4
		28 0x9a0 0x5
		28 0x9c0 0x4
		28 0x9e0 0x5
		28 0xa00 0x4
		28 0xa20 0x5
		28 0xa40 0x4
		28 0xa60 0x5
		28 0xa80 0x4
		28 0xaa0 0x5
		29 0x2c0 0x4
		29 0x2e0 0x5
		29 0x300 0x4
		29 0x320 0x5
		29 0x340 0x4
		29 0x360 0x5
		29 0x380 0x4
		29 0x3a0 0x5
		28 0x0 0x30001
		29 0x0 0x30001
		6 0x110 0x0
		6 0x114 0x0
		6 0x100 0x4
		6 0x130 0x0
		6 0x134 0x0
		6 0x120 0x4
		6 0x150 0x0
		6 0x154 0x0
		6 0x140 0x4
		6 0x170 0x0
		6 0x174 0x0
		6 0x160 0x4
		6 0x190 0x0
		6 0x194 0x0
		6 0x180 0x4
		6 0x1b0 0x0
		6 0x1b4 0x0
		6 0x1a0 0x4
		6 0x1d0 0x0
		6 0x1d4 0x0
		6 0x1c0 0x4
		6 0x1f0 0x0
		6 0x1f4 0x0
		6 0x1e0 0x4
		6 0x210 0x0
		6 0x214 0x0
		6 0x200 0x4
		6 0x230 0x0
		6 0x234 0x0
		6 0x220 0x4
		6 0x250 0x0
		6 0x254 0x0
		6 0x240 0x4
		6 0x270 0x0
		6 0x274 0x0
		6 0x260 0x4
		6 0x290 0x0
		6 0x294 0x0
		6 0x280 0x4
		6 0x2b0 0x0
		6 0x2b4 0x0
		6 0x2a0 0x4
		6 0x2d0 0x0
		6 0x2d4 0x0
		6 0x2c0 0x4
		6 0x2f0 0x0
		6 0x2f4 0x0
		6 0x2e0 0x4
		6 0x310 0x0
		6 0x314 0x0
		6 0x300 0x4
		6 0x330 0x0
		6 0x334 0x0
		6 0x320 0x4
		6 0x350 0x0
		6 0x354 0x0
		6 0x340 0x4
		6 0x370 0x0
		6 0x374 0x0
		6 0x360 0x4
		6 0x390 0x0
		6 0x394 0x0
		6 0x380 0x4
		6 0x3b0 0x0
		6 0x3b4 0x0
		6 0x3a0 0x4
		6 0x3d0 0x0
		6 0x3d4 0x0
		6 0x3c0 0x4
		6 0x3f0 0x0
		6 0x3f4 0x0
		6 0x3e0 0x4
		6 0x410 0x0
		6 0x414 0x0
		6 0x400 0x4
		6 0x430 0x0
		6 0x434 0x0
		6 0x420 0x4
		6 0x450 0x0
		6 0x454 0x0
		6 0x440 0x4
		6 0x470 0x0
		6 0x474 0x0
		6 0x460 0x4
		6 0x490 0x0
		6 0x494 0x0
		6 0x480 0x4
		6 0x4b0 0x0
		6 0x4b4 0x0
		6 0x4a0 0x4
		6 0x4d0 0x0
		6 0x4d4 0x0
		6 0x4c0 0x4
		6 0x4f0 0x0
		6 0x4f4 0x0
		6 0x4e0 0x4
		6 0x510 0x0
		6 0x514 0x0
		6 0x500 0x4
		6 0x530 0x0
		6 0x534 0x0
		6 0x520 0x4
		6 0x550 0x0
		6 0x554 0x0
		6 0x540 0x4
		6 0x570 0x0
		6 0x574 0x0
		6 0x560 0x4
		6 0x590 0x0
		6 0x594 0x0
		6 0x580 0x4
		6 0x5b0 0x0
		6 0x5b4 0x0
		6 0x5a0 0x4
		6 0x5d0 0x0
		6 0x5d4 0x0
		6 0x5c0 0x4
		6 0x5f0 0x0
		6 0x5f4 0x0
		6 0x5e0 0x4
		6 0x610 0x0
		6 0x614 0x0
		6 0x600 0x4
		6 0x630 0x0
		6 0x634 0x0
		6 0x620 0x4
		6 0x650 0x0
		6 0x654 0x0
		6 0x640 0x4
		6 0x670 0x0
		6 0x674 0x0
		6 0x660 0x4
		6 0x690 0x0
		6 0x694 0x0
		6 0x680 0x4
		8 0x110 0x0
		8 0x114 0x0
		8 0x100 0x4
		8 0x130 0x0
		8 0x134 0x0
		8 0x120 0x4
		8 0x150 0x0
		8 0x154 0x0
		8 0x140 0x4
		8 0x170 0x0
		8 0x174 0x0
		8 0x160 0x4
		8 0x190 0x0
		8 0x194 0x0
		8 0x180 0x4
		8 0x1b0 0x0
		8 0x1b4 0x0
		8 0x1a0 0x4
		8 0x1d0 0x0
		8 0x1d4 0x0
		8 0x1c0 0x4
		8 0x1f0 0x0
		8 0x1f4 0x0
		8 0x1e0 0x4
		8 0x210 0x0
		8 0x214 0x0
		8 0x200 0x4
		8 0x230 0x0
		8 0x234 0x0
		8 0x220 0x4
		8 0x250 0x0
		8 0x254 0x0
		8 0x240 0x4
		8 0x270 0x0
		8 0x274 0x0
		8 0x260 0x4
		8 0x290 0x0
		8 0x294 0x0
		8 0x280 0x4
		8 0x2b0 0x0
		8 0x2b4 0x0
		8 0x2a0 0x4
		8 0x2d0 0x0
		8 0x2d4 0x0
		8 0x2c0 0x4
		8 0x2f0 0x0
		8 0x2f4 0x0
		8 0x2e0 0x4
		8 0x310 0x0
		8 0x314 0x0
		8 0x300 0x4
		8 0x330 0x0
		8 0x334 0x0
		8 0x320 0x4
		8 0x350 0x0
		8 0x354 0x0
		8 0x340 0x4
		8 0x370 0x0
		8 0x374 0x0
		8 0x360 0x4
		8 0x390 0x0
		8 0x394 0x0
		8 0x380 0x4
		8 0x3b0 0x0
		8 0x3b4 0x0
		8 0x3a0 0x4
		8 0x3d0 0x0
		8 0x3d4 0x0
		8 0x3c0 0x4
		8 0x3f0 0x0
		8 0x3f4 0x0
		8 0x3e0 0x4
		8 0x410 0x0
		8 0x414 0x0
		8 0x400 0x4
		8 0x430 0x0
		8 0x434 0x0
		8 0x420 0x4
		8 0x450 0x0
		8 0x454 0x0
		8 0x440 0x4
		8 0x470 0x0
		8 0x474 0x0
		8 0x460 0x4
		8 0x490 0x0
		8 0x494 0x0
		8 0x480 0x4
		10 0x110 0x0
		10 0x114 0x0
		10 0x100 0x4
		10 0x130 0x0
		10 0x134 0x0
		10 0x120 0x4
		10 0x150 0x0
		10 0x154 0x0
		10 0x140 0x4
		10 0x170 0x0
		10 0x174 0x0
		10 0x160 0x4
		10 0x190 0x0
		10 0x194 0x0
		10 0x180 0x4
		10 0x1b0 0x0
		10 0x1b4 0x0
		10 0x1a0 0x4
		10 0x1d0 0x0
		10 0x1d4 0x0
		10 0x1c0 0x4
		10 0x1f0 0x0
		10 0x1f4 0x0
		10 0x1e0 0x4
		10 0x210 0x0
		10 0x214 0x0
		10 0x200 0x4
		10 0x230 0x0
		10 0x234 0x0
		10 0x220 0x4
		10 0x250 0x0
		10 0x254 0x0
		10 0x240 0x4
		10 0x270 0x0
		10 0x274 0x0
		10 0x260 0x4
		10 0x290 0x0
		10 0x294 0x0
		10 0x280 0x4
		10 0x2b0 0x0
		10 0x2b4 0x0
		10 0x2a0 0x4
		10 0x2d0 0x0
		10 0x2d4 0x0
		10 0x2c0 0x4
		10 0x2f0 0x0
		10 0x2f4 0x0
		10 0x2e0 0x4
		10 0x310 0x0
		10 0x314 0x0
		10 0x300 0x4
		10 0x330 0x0
		10 0x334 0x0
		10 0x320 0x4
		10 0x350 0x0
		10 0x354 0x0
		10 0x340 0x4
		10 0x370 0x0
		10 0x374 0x0
		10 0x360 0x4
		10 0x390 0x0
		10 0x394 0x0
		10 0x380 0x4
		10 0x3b0 0x0
		10 0x3b4 0x0
		10 0x3a0 0x4
		10 0x3d0 0x0
		10 0x3d4 0x0
		10 0x3c0 0x4
		10 0x3f0 0x0
		10 0x3f4 0x0
		10 0x3e0 0x4
		10 0x410 0x0
		10 0x414 0x0
		10 0x400 0x4
		10 0x430 0x0
		10 0x434 0x0
		10 0x420 0x4
		10 0x450 0x0
		10 0x454 0x0
		10 0x440 0x4
		10 0x470 0x0
		10 0x474 0x0
		10 0x460 0x4
		10 0x490 0x0
		10 0x494 0x0
		10 0x480 0x4
		10 0x4b0 0x0
		10 0x4b4 0x0
		10 0x4a0 0x4
		10 0x4d0 0x0
		10 0x4d4 0x0
		10 0x4c0 0x4
		10 0x4f0 0x0
		10 0x4f4 0x0
		10 0x4e0 0x4
		10 0x510 0x0
		10 0x514 0x0
		10 0x500 0x4
		10 0x530 0x0
		10 0x534 0x0
		10 0x520 0x4
		10 0x550 0x0
		10 0x554 0x0
		10 0x540 0x4
		10 0x570 0x0
		10 0x574 0x0
		10 0x560 0x4
		10 0x590 0x0
		10 0x594 0x0
		10 0x580 0x4
		10 0x5b0 0x0
		10 0x5b4 0x0
		10 0x5a0 0x4
		10 0x5d0 0x0
		10 0x5d4 0x0
		10 0x5c0 0x4
		10 0x5f0 0x0
		10 0x5f4 0x0
		10 0x5e0 0x4
		10 0x610 0x0
		10 0x614 0x0
		10 0x600 0x4
		10 0x630 0x0
		10 0x634 0x0
		10 0x620 0x4
		10 0x650 0x0
		10 0x654 0x0
		10 0x640 0x4
		10 0x670 0x0
		10 0x674 0x0
		10 0x660 0x4
		10 0x690 0x0
		10 0x694 0x0
		10 0x680 0x4
		10 0x6b0 0x0
		10 0x6b4 0x0
		10 0x6a0 0x4
		10 0x6d0 0x0
		10 0x6d4 0x0
		10 0x6c0 0x4
		10 0x6f0 0x0
		10 0x6f4 0x0
		10 0x6e0 0x4
		10 0x710 0x0
		10 0x714 0x0
		10 0x700 0x4
		10 0x730 0x0
		10 0x734 0x0
		10 0x720 0x4
		10 0x750 0x0
		10 0x754 0x0
		10 0x740 0x4
		10 0x770 0x0
		10 0x774 0x0
		10 0x760 0x4
		10 0x790 0x0
		10 0x794 0x0
		10 0x780 0x4
		10 0x7b0 0x0
		10 0x7b4 0x0
		10 0x7a0 0x4
		10 0x7d0 0x0
		10 0x7d4 0x0
		10 0x7c0 0x4
		10 0x7f0 0x0
		10 0x7f4 0x0
		10 0x7e0 0x4
		10 0x810 0x0
		10 0x814 0x0
		10 0x800 0x4
		10 0x830 0x0
		10 0x834 0x0
		10 0x820 0x4
		10 0x850 0x0
		10 0x854 0x0
		10 0x840 0x4
		10 0x870 0x0
		10 0x874 0x0
		10 0x860 0x4
		10 0x890 0x0
		10 0x894 0x0
		10 0x880 0x4
		10 0x8b0 0x0
		10 0x8b4 0x0
		10 0x8a0 0x4
		10 0x8d0 0x0
		10 0x8d4 0x0
		10 0x8c0 0x4
		10 0x8f0 0x0
		10 0x8f4 0x0
		10 0x8e0 0x4
		10 0x910 0x0
		10 0x914 0x0
		10 0x900 0x4
		10 0x930 0x0
		10 0x934 0x0
		10 0x920 0x4
		10 0x950 0x0
		10 0x954 0x0
		10 0x940 0x4
		10 0x970 0x0
		10 0x974 0x0
		10 0x960 0x4
		10 0x990 0x0
		10 0x994 0x0
		10 0x980 0x4
		10 0x9b0 0x0
		10 0x9b4 0x0
		10 0x9a0 0x4
		10 0x9d0 0x0
		10 0x9d4 0x0
		10 0x9c0 0x4
		10 0x9f0 0x0
		10 0x9f4 0x0
		10 0x9e0 0x4
		10 0xa10 0x0
		10 0xa14 0x0
		10 0xa00 0x4
		10 0xa30 0x0
		10 0xa34 0x0
		10 0xa20 0x4
		10 0xa50 0x0
		10 0xa54 0x0
		10 0xa40 0x4
		10 0xa70 0x0
		10 0xa74 0x0
		10 0xa60 0x4
		10 0xa90 0x0
		10 0xa94 0x0
		10 0xa80 0x4
		10 0xab0 0x0
		10 0xab4 0x0
		10 0xaa0 0x4
		10 0xad0 0x0
		10 0xad4 0x0
		10 0xac0 0x4
		10 0xaf0 0x0
		10 0xaf4 0x0
		10 0xae0 0x4
		10 0xb10 0x0
		10 0xb14 0x0
		10 0xb00 0x4
		10 0xb30 0x0
		10 0xb34 0x0
		10 0xb20 0x4
		10 0xb50 0x0
		10 0xb54 0x0
		10 0xb40 0x4
		10 0xb70 0x0
		10 0xb74 0x0
		10 0xb60 0x4
		10 0xb90 0x0
		10 0xb94 0x0
		10 0xb80 0x4
		10 0xbb0 0x0
		10 0xbb4 0x0
		10 0xba0 0x4
		10 0xbd0 0x0
		10 0xbd4 0x0
		10 0xbc0 0x4
		10 0xbf0 0x0
		10 0xbf4 0x0
		10 0xbe0 0x4
		10 0xc10 0x0
		10 0xc14 0x0
		10 0xc00 0x4
		10 0xc30 0x0
		10 0xc34 0x0
		10 0xc20 0x4
		10 0xc50 0x0
		10 0xc54 0x0
		10 0xc40 0x4
		10 0xc70 0x0
		10 0xc74 0x0
		10 0xc60 0x4
		10 0xc90 0x0
		10 0xc94 0x0
		10 0xc80 0x4
		10 0xcb0 0x0
		10 0xcb4 0x0
		10 0xca0 0x4
		10 0xcd0 0x0
		10 0xcd4 0x0
		10 0xcc0 0x4
		10 0xcf0 0x0
		10 0xcf4 0x0
		10 0xce0 0x4
		10 0xd10 0x0
		10 0xd14 0x0
		10 0xd00 0x4
		10 0xd30 0x0
		10 0xd34 0x0
		10 0xd20 0x4
		10 0xd50 0x0
		10 0xd54 0x0
		10 0xd40 0x4
		10 0xd70 0x0
		10 0xd74 0x0
		10 0xd60 0x4
		10 0xd90 0x0
		10 0xd94 0x0
		10 0xd80 0x4
		10 0xdb0 0x0
		10 0xdb4 0x0
		10 0xda0 0x4
		10 0xdd0 0x0
		10 0xdd4 0x0
		10 0xdc0 0x4
		10 0xdf0 0x0
		10 0xdf4 0x0
		10 0xde0 0x4
		10 0xe10 0x0
		10 0xe14 0x0
		10 0xe00 0x4
		10 0xe30 0x0
		10 0xe34 0x0
		10 0xe20 0x4
		10 0xe50 0x0
		10 0xe54 0x0
		10 0xe40 0x4
		10 0xe70 0x0
		10 0xe74 0x0
		10 0xe60 0x4
		10 0xe90 0x0
		10 0xe94 0x0
		10 0xe80 0x4
		10 0xeb0 0x0
		10 0xeb4 0x0
		10 0xea0 0x4
		10 0xed0 0x0
		10 0xed4 0x0
		10 0xec0 0x4
		10 0xef0 0x0
		10 0xef4 0x0
		10 0xee0 0x4
		10 0xf10 0x0
		10 0xf14 0x0
		10 0xf00 0x4
		10 0xf30 0x0
		10 0xf34 0x0
		10 0xf20 0x4
		10 0xf50 0x0
		10 0xf54 0x0
		10 0xf40 0x4
		10 0xf70 0x0
		10 0xf74 0x0
		10 0xf60 0x4
		10 0xf90 0x0
		10 0xf94 0x0
		10 0xf80 0x4
		10 0xfb0 0x0
		10 0xfb4 0x0
		10 0xfa0 0x4
		10 0xfd0 0x0
		10 0xfd4 0x0
		10 0xfc0 0x4
		10 0xff0 0x0
		10 0xff4 0x0
		10 0xfe0 0x4
		10 0x1010 0x0
		10 0x1014 0x0
		10 0x1000 0x4
		10 0x1030 0x0
		10 0x1034 0x0
		10 0x1020 0x4
		10 0x1050 0x0
		10 0x1054 0x0
		10 0x1040 0x4
		10 0x1070 0x0
		10 0x1074 0x0
		10 0x1060 0x4
		10 0x1090 0x0
		10 0x1094 0x0
		10 0x1080 0x4
		10 0x10b0 0x0
		10 0x10b4 0x0
		10 0x10a0 0x4
		10 0x10d0 0x0
		10 0x10d4 0x0
		10 0x10c0 0x4
		10 0x10f0 0x0
		10 0x10f4 0x0
		10 0x10e0 0x4
		10 0x1110 0x0
		10 0x1114 0x0
		10 0x1100 0x4
		10 0x1130 0x0
		10 0x1134 0x0
		10 0x1120 0x4
		10 0x1150 0x0
		10 0x1154 0x0
		10 0x1140 0x4
		10 0x1170 0x0
		10 0x1174 0x0
		10 0x1160 0x4
		6 0x6b0 0x0
		6 0x6b4 0x0
		6 0x6a0 0x4
		6 0x6d0 0x0
		6 0x6d4 0x0
		6 0x6c0 0x4
		6 0x6f0 0x0
		6 0x6f4 0x0
		6 0x6e0 0x4
		6 0x710 0x0
		6 0x714 0x0
		6 0x700 0x4
		6 0x730 0x0
		6 0x734 0x0
		6 0x720 0x4
		6 0x750 0x0
		6 0x754 0x0
		6 0x740 0x4
		6 0x770 0x0
		6 0x774 0x0
		6 0x760 0x4
		6 0x790 0x0
		6 0x794 0x0
		6 0x780 0x4
		6 0x7b0 0x0
		6 0x7b4 0x0
		6 0x7a0 0x4
		6 0x7d0 0x0
		6 0x7d4 0x0
		6 0x7c0 0x4
		8 0x4b0 0x0
		8 0x4b4 0x0
		8 0x4a0 0x4
		8 0x4d0 0x0
		8 0x4d4 0x0
		8 0x4c0 0x4
		8 0x4f0 0x0
		8 0x4f4 0x0
		8 0x4e0 0x4
		8 0x510 0x0
		8 0x514 0x0
		8 0x500 0x4
		8 0x530 0x0
		8 0x534 0x0
		8 0x520 0x4
		8 0x550 0x0
		8 0x554 0x0
		8 0x540 0x4
		8 0x570 0x0
		8 0x574 0x0
		8 0x560 0x4
		8 0x590 0x0
		8 0x594 0x0
		8 0x580 0x4
		10 0x1190 0x0
		10 0x1194 0x0
		10 0x1180 0x4
		10 0x11b0 0x0
		10 0x11b4 0x0
		10 0x11a0 0x4
		10 0x11d0 0x0
		10 0x11d4 0x0
		10 0x11c0 0x4
		10 0x11f0 0x0
		10 0x11f4 0x0
		10 0x11e0 0x4
		10 0x1210 0x0
		10 0x1214 0x0
		10 0x1200 0x4
		10 0x1230 0x0
		10 0x1234 0x0
		10 0x1220 0x4
		10 0x1250 0x0
		10 0x1254 0x0
		10 0x1240 0x4
		10 0x1270 0x0
		10 0x1274 0x0
		10 0x1260 0x4
		10 0x1290 0x0
		10 0x1294 0x0
		10 0x1280 0x4
		10 0x12b0 0x0
		10 0x12b4 0x0
		10 0x12a0 0x4
		10 0x12d0 0x0
		10 0x12d4 0x0
		10 0x12c0 0x4
		10 0x12f0 0x0
		10 0x12f4 0x0
		10 0x12e0 0x4
		10 0x1310 0x0
		10 0x1314 0x0
		10 0x1300 0x4
		10 0x1330 0x0
		10 0x1334 0x0
		10 0x1320 0x4
		10 0x1350 0x0
		10 0x1354 0x0
		10 0x1340 0x4
		10 0x1370 0x0
		10 0x1374 0x0
		10 0x1360 0x4
		6 0x7f0 0x0
		6 0x7f4 0x0
		6 0x7e0 0x4
		6 0x810 0x0
		6 0x814 0x0
		6 0x800 0x4
		6 0x830 0x0
		6 0x834 0x0
		6 0x820 0x4
		6 0x850 0x0
		6 0x854 0x0
		6 0x840 0x4
		6 0x870 0x0
		6 0x874 0x0
		6 0x860 0x4
		6 0x890 0x0
		6 0x894 0x0
		6 0x880 0x4
		6 0x8b0 0x0
		6 0x8b4 0x0
		6 0x8a0 0x4
		6 0x8d0 0x0
		6 0x8d4 0x0
		6 0x8c0 0x4
		6 0x8f0 0x0
		6 0x8f4 0x0
		6 0x8e0 0x4
		6 0x910 0x0
		6 0x914 0x0
		6 0x900 0x4
		6 0x930 0x0
		6 0x934 0x0
		6 0x920 0x4
		6 0x950 0x0
		6 0x954 0x0
		6 0x940 0x4
		6 0x970 0x0
		6 0x974 0x0
		6 0x960 0x4
		6 0x990 0x0
		6 0x994 0x0
		6 0x980 0x4
		6 0x9b0 0x0
		6 0x9b4 0x0
		6 0x9a0 0x4
		6 0x9d0 0x0
		6 0x9d4 0x0
		6 0x9c0 0x4
		6 0x9f0 0x0
		6 0x9f4 0x0
		6 0x9e0 0x4
		6 0xa10 0x0
		6 0xa14 0x0
		6 0xa00 0x4
		6 0xa30 0x0
		6 0xa34 0x0
		6 0xa20 0x4
		6 0xa50 0x0
		6 0xa54 0x0
		6 0xa40 0x4
		6 0xa70 0x0
		6 0xa74 0x0
		6 0xa60 0x4
		6 0xa90 0x0
		6 0xa94 0x0
		6 0xa80 0x4
		6 0xab0 0x0
		6 0xab4 0x0
		6 0xaa0 0x4
		6 0xad0 0x0
		6 0xad4 0x0
		6 0xac0 0x4
		6 0xaf0 0x0
		6 0xaf4 0x0
		6 0xae0 0x4
		6 0xb10 0x0
		6 0xb14 0x0
		6 0xb00 0x4
		6 0xb30 0x0
		6 0xb34 0x0
		6 0xb20 0x4
		6 0xb50 0x0
		6 0xb54 0x0
		6 0xb40 0x4
		8 0x5b0 0x0
		8 0x5b4 0x0
		8 0x5a0 0x4
		8 0x5d0 0x0
		8 0x5d4 0x0
		8 0x5c0 0x4
		8 0x5f0 0x0
		8 0x5f4 0x0
		8 0x5e0 0x4
		8 0x610 0x0
		8 0x614 0x0
		8 0x600 0x4
		8 0x630 0x0
		8 0x634 0x0
		8 0x620 0x4
		8 0x650 0x0
		8 0x654 0x0
		8 0x640 0x4
		8 0x670 0x0
		8 0x674 0x0
		8 0x660 0x4
		8 0x690 0x0
		8 0x694 0x0
		8 0x680 0x4
		8 0x6b0 0x0
		8 0x6b4 0x0
		8 0x6a0 0x4
		8 0x6d0 0x0
		8 0x6d4 0x0
		8 0x6c0 0x4
		8 0x6f0 0x0
		8 0x6f4 0x0
		8 0x6e0 0x4
		8 0x710 0x0
		8 0x714 0x0
		8 0x700 0x4
		8 0x730 0x0
		8 0x734 0x0
		8 0x720 0x4
		8 0x750 0x0
		8 0x754 0x0
		8 0x740 0x4
		8 0x770 0x0
		8 0x774 0x0
		8 0x760 0x4
		8 0x790 0x0
		8 0x794 0x0
		8 0x780 0x4
		8 0x7b0 0x0
		8 0x7b4 0x0
		8 0x7a0 0x4
		8 0x7d0 0x0
		8 0x7d4 0x0
		8 0x7c0 0x4
		8 0x7f0 0x0
		8 0x7f4 0x0
		8 0x7e0 0x4
		8 0x810 0x0
		8 0x814 0x0
		8 0x800 0x4
		8 0x830 0x0
		8 0x834 0x0
		8 0x820 0x4
		8 0x850 0x0
		8 0x854 0x0
		8 0x840 0x4
		8 0x870 0x0
		8 0x874 0x0
		8 0x860 0x4
		8 0x890 0x0
		8 0x894 0x0
		8 0x880 0x4
		8 0x8b0 0x0
		8 0x8b4 0x0
		8 0x8a0 0x4
		10 0x1390 0x0
		10 0x1394 0x0
		10 0x1380 0x4
		10 0x13b0 0x0
		10 0x13b4 0x0
		10 0x13a0 0x4
		10 0x13d0 0x0
		10 0x13d4 0x0
		10 0x13c0 0x4
		10 0x13f0 0x0
		10 0x13f4 0x0
		10 0x13e0 0x4
		10 0x1410 0x0
		10 0x1414 0x0
		10 0x1400 0x4
		10 0x1430 0x0
		10 0x1434 0x0
		10 0x1420 0x4
		10 0x1450 0x0
		10 0x1454 0x0
		10 0x1440 0x4
		10 0x1470 0x0
		10 0x1474 0x0
		10 0x1460 0x4
		10 0x1490 0x0
		10 0x1494 0x0
		10 0x1480 0x4
		10 0x14b0 0x0
		10 0x14b4 0x0
		10 0x14a0 0x4
		10 0x14d0 0x0
		10 0x14d4 0x0
		10 0x14c0 0x4
		10 0x14f0 0x0
		10 0x14f4 0x0
		10 0x14e0 0x4
		10 0x1510 0x0
		10 0x1514 0x0
		10 0x1500 0x4
		10 0x1530 0x0
		10 0x1534 0x0
		10 0x1520 0x4
		10 0x1550 0x0
		10 0x1554 0x0
		10 0x1540 0x4
		10 0x1570 0x0
		10 0x1574 0x0
		10 0x1560 0x4
		10 0x1590 0x0
		10 0x1594 0x0
		10 0x1580 0x4
		10 0x15b0 0x0
		10 0x15b4 0x0
		10 0x15a0 0x4
		10 0x15d0 0x0
		10 0x15d4 0x0
		10 0x15c0 0x4
		10 0x15f0 0x0
		10 0x15f4 0x0
		10 0x15e0 0x4
		10 0x1610 0x0
		10 0x1614 0x0
		10 0x1600 0x4
		10 0x1630 0x0
		10 0x1634 0x0
		10 0x1620 0x4
		10 0x1650 0x0
		10 0x1654 0x0
		10 0x1640 0x4
		10 0x1670 0x0
		10 0x1674 0x0
		10 0x1660 0x4
		10 0x1690 0x0
		10 0x1694 0x0
		10 0x1680 0x4
		10 0x16b0 0x0
		10 0x16b4 0x0
		10 0x16a0 0x4
		10 0x16d0 0x0
		10 0x16d4 0x0
		10 0x16c0 0x4
		10 0x16f0 0x0
		10 0x16f4 0x0
		10 0x16e0 0x4
		10 0x1710 0x0
		10 0x1714 0x0
		10 0x1700 0x4
		10 0x1730 0x0
		10 0x1734 0x0
		10 0x1720 0x4
		10 0x1750 0x0
		10 0x1754 0x0
		10 0x1740 0x4
		10 0x1770 0x0
		10 0x1774 0x0
		10 0x1760 0x4
		10 0x1790 0x0
		10 0x1794 0x0
		10 0x1780 0x4
		10 0x17b0 0x0
		10 0x17b4 0x0
		10 0x17a0 0x4
		10 0x17d0 0x0
		10 0x17d4 0x0
		10 0x17c0 0x4
		10 0x17f0 0x0
		10 0x17f4 0x0
		10 0x17e0 0x4
		10 0x1810 0x0
		10 0x1814 0x0
		10 0x1800 0x4
		10 0x1830 0x0
		10 0x1834 0x0
		10 0x1820 0x4
		10 0x1850 0x0
		10 0x1854 0x0
		10 0x1840 0x4
		10 0x1870 0x0
		10 0x1874 0x0
		10 0x1860 0x4
		10 0x1890 0x0
		10 0x1894 0x0
		10 0x1880 0x4
		10 0x18b0 0x0
		10 0x18b4 0x0
		10 0x18a0 0x4
		10 0x18d0 0x0
		10 0x18d4 0x0
		10 0x18c0 0x4
		10 0x18f0 0x0
		10 0x18f4 0x0
		10 0x18e0 0x4
		10 0x1910 0x0
		10 0x1914 0x0
		10 0x1900 0x4
		10 0x1930 0x0
		10 0x1934 0x0
		10 0x1920 0x4
		10 0x1950 0x0
		10 0x1954 0x0
		10 0x1940 0x4
		10 0x1970 0x0
		10 0x1974 0x0
		10 0x1960 0x4
		10 0x1990 0x0
		10 0x1994 0x0
		10 0x1980 0x4
		10 0x19b0 0x0
		10 0x19b4 0x0
		10 0x19a0 0x4
		10 0x19d0 0x0
		10 0x19d4 0x0
		10 0x19c0 0x4
		10 0x19f0 0x0
		10 0x19f4 0x0
		10 0x19e0 0x4
		10 0x1a10 0x0
		10 0x1a14 0x0
		10 0x1a00 0x4
		10 0x1a30 0x0
		10 0x1a34 0x0
		10 0x1a20 0x4
		10 0x1a50 0x0
		10 0x1a54 0x0
		10 0x1a40 0x4
		10 0x1a70 0x0
		10 0x1a74 0x0
		10 0x1a60 0x4
		10 0x1a90 0x0
		10 0x1a94 0x0
		10 0x1a80 0x4
		10 0x1ab0 0x0
		10 0x1ab4 0x0
		10 0x1aa0 0x4
		10 0x1ad0 0x0
		10 0x1ad4 0x0
		10 0x1ac0 0x4
		10 0x1af0 0x0
		10 0x1af4 0x0
		10 0x1ae0 0x4
		10 0x1b10 0x0
		10 0x1b14 0x0
		10 0x1b00 0x4
		10 0x1b30 0x0
		10 0x1b34 0x0
		10 0x1b20 0x4
		10 0x1b50 0x0
		10 0x1b54 0x0
		10 0x1b40 0x4
		6 0xb70 0x0
		6 0xb74 0x0
		6 0xb90 0x0
		6 0xb94 0x0
		6 0xb60 0x4
		6 0xb80 0x5
		6 0xbb0 0x0
		6 0xbb4 0x0
		6 0xbd0 0x0
		6 0xbd4 0x0
		6 0xba0 0x4
		6 0xbc0 0x5
		6 0xbf0 0x0
		6 0xbf4 0x0
		6 0xc10 0x0
		6 0xc14 0x0
		6 0xbe0 0x4
		6 0xc00 0x5
		6 0xc30 0x0
		6 0xc34 0x0
		6 0xc50 0x0
		6 0xc54 0x0
		6 0xc20 0x4
		6 0xc40 0x5
		6 0xc70 0x0
		6 0xc74 0x0
		6 0xc90 0x0
		6 0xc94 0x0
		6 0xc60 0x4
		6 0xc80 0x5
		6 0xcb0 0x0
		6 0xcb4 0x0
		6 0xcd0 0x0
		6 0xcd4 0x0
		6 0xca0 0x4
		6 0xcc0 0x5
		6 0xcf0 0x0
		6 0xcf4 0x0
		6 0xd10 0x0
		6 0xd14 0x0
		6 0xce0 0x4
		6 0xd00 0x5
		6 0xd30 0x0
		6 0xd34 0x0
		6 0xd50 0x0
		6 0xd54 0x0
		6 0xd20 0x4
		6 0xd40 0x5
		6 0xd70 0x0
		6 0xd74 0x0
		6 0xd90 0x0
		6 0xd94 0x0
		6 0xd60 0x4
		6 0xd80 0x5
		6 0xdb0 0x0
		6 0xdb4 0x0
		6 0xdd0 0x0
		6 0xdd4 0x0
		6 0xda0 0x4
		6 0xdc0 0x5
		6 0xdf0 0x0
		6 0xdf4 0x0
		6 0xe10 0x0
		6 0xe14 0x0
		6 0xde0 0x4
		6 0xe00 0x5
		6 0xe30 0x0
		6 0xe34 0x0
		6 0xe50 0x0
		6 0xe54 0x0
		6 0xe20 0x4
		6 0xe40 0x5
		6 0xe70 0x0
		6 0xe74 0x0
		6 0xe90 0x0
		6 0xe94 0x0
		6 0xe60 0x4
		6 0xe80 0x5
		6 0xeb0 0x0
		6 0xeb4 0x0
		6 0xed0 0x0
		6 0xed4 0x0
		6 0xea0 0x4
		6 0xec0 0x5
		6 0xef0 0x0
		6 0xef4 0x0
		6 0xf10 0x0
		6 0xf14 0x0
		6 0xee0 0x4
		6 0xf00 0x5
		6 0xf30 0x0
		6 0xf34 0x0
		6 0xf50 0x0
		6 0xf54 0x0
		6 0xf20 0x4
		6 0xf40 0x5
		6 0xf70 0x0
		6 0xf74 0x0
		6 0xf90 0x0
		6 0xf94 0x0
		6 0xf60 0x4
		6 0xf80 0x5
		6 0xfb0 0x0
		6 0xfb4 0x0
		6 0xfd0 0x0
		6 0xfd4 0x0
		6 0xfa0 0x4
		6 0xfc0 0x5
		6 0xff0 0x0
		6 0xff4 0x0
		6 0x1010 0x0
		6 0x1014 0x0
		6 0xfe0 0x4
		6 0x1000 0x5
		6 0x1030 0x0
		6 0x1034 0x0
		6 0x1050 0x0
		6 0x1054 0x0
		6 0x1020 0x4
		6 0x1040 0x5
		6 0x1070 0x0
		6 0x1074 0x0
		6 0x1090 0x0
		6 0x1094 0x0
		6 0x1060 0x4
		6 0x1080 0x5
		6 0x10b0 0x0
		6 0x10b4 0x0
		6 0x10d0 0x0
		6 0x10d4 0x0
		6 0x10a0 0x4
		6 0x10c0 0x5
		6 0x10f0 0x0
		6 0x10f4 0x0
		6 0x1110 0x0
		6 0x1114 0x0
		6 0x10e0 0x4
		6 0x1100 0x5
		6 0x1130 0x0
		6 0x1134 0x0
		6 0x1150 0x0
		6 0x1154 0x0
		6 0x1120 0x4
		6 0x1140 0x5
		6 0x1170 0x0
		6 0x1174 0x0
		6 0x1190 0x0
		6 0x1194 0x0
		6 0x1160 0x4
		6 0x1180 0x5
		6 0x11b0 0x0
		6 0x11b4 0x0
		6 0x11d0 0x0
		6 0x11d4 0x0
		6 0x11a0 0x4
		6 0x11c0 0x5
		6 0x11f0 0x0
		6 0x11f4 0x0
		6 0x1210 0x0
		6 0x1214 0x0
		6 0x11e0 0x4
		6 0x1200 0x5
		6 0x1230 0x0
		6 0x1234 0x0
		6 0x1250 0x0
		6 0x1254 0x0
		6 0x1220 0x4
		6 0x1240 0x5
		6 0x1270 0x0
		6 0x1274 0x0
		6 0x1290 0x0
		6 0x1294 0x0
		6 0x1260 0x4
		6 0x1280 0x5
		6 0x12b0 0x0
		6 0x12b4 0x0
		6 0x12d0 0x0
		6 0x12d4 0x0
		6 0x12a0 0x4
		6 0x12c0 0x5
		6 0x12f0 0x0
		6 0x12f4 0x0
		6 0x1310 0x0
		6 0x1314 0x0
		6 0x12e0 0x4
		6 0x1300 0x5
		6 0x1330 0x0
		6 0x1334 0x0
		6 0x1350 0x0
		6 0x1354 0x0
		6 0x1320 0x4
		6 0x1340 0x5
		6 0x1370 0x0
		6 0x1374 0x0
		6 0x1390 0x0
		6 0x1394 0x0
		6 0x1360 0x4
		6 0x1380 0x5
		6 0x13b0 0x0
		6 0x13b4 0x0
		6 0x13d0 0x0
		6 0x13d4 0x0
		6 0x13a0 0x4
		6 0x13c0 0x5
		6 0x13f0 0x0
		6 0x13f4 0x0
		6 0x1410 0x0
		6 0x1414 0x0
		6 0x13e0 0x4
		6 0x1400 0x5
		6 0x1430 0x0
		6 0x1434 0x0
		6 0x1450 0x0
		6 0x1454 0x0
		6 0x1420 0x4
		6 0x1440 0x5
		6 0x1470 0x0
		6 0x1474 0x0
		6 0x1490 0x0
		6 0x1494 0x0
		6 0x1460 0x4
		6 0x1480 0x5
		6 0x14b0 0x0
		6 0x14b4 0x0
		6 0x14d0 0x0
		6 0x14d4 0x0
		6 0x14a0 0x4
		6 0x14c0 0x5
		6 0x14f0 0x0
		6 0x14f4 0x0
		6 0x1510 0x0
		6 0x1514 0x0
		6 0x14e0 0x4
		6 0x1500 0x5
		6 0x1530 0x0
		6 0x1534 0x0
		6 0x1550 0x0
		6 0x1554 0x0
		6 0x1520 0x4
		6 0x1540 0x5
		6 0x1570 0x0
		6 0x1574 0x0
		6 0x1590 0x0
		6 0x1594 0x0
		6 0x1560 0x4
		6 0x1580 0x5
		6 0x15b0 0x0
		6 0x15b4 0x0
		6 0x15d0 0x0
		6 0x15d4 0x0
		6 0x15a0 0x4
		6 0x15c0 0x5
		6 0x15f0 0x0
		6 0x15f4 0x0
		6 0x1610 0x0
		6 0x1614 0x0
		6 0x15e0 0x4
		6 0x1600 0x5
		6 0x1630 0x0
		6 0x1634 0x0
		6 0x1650 0x0
		6 0x1654 0x0
		6 0x1620 0x4
		6 0x1640 0x5
		6 0x1670 0x0
		6 0x1674 0x0
		6 0x1690 0x0
		6 0x1694 0x0
		6 0x1660 0x4
		6 0x1680 0x5
		6 0x16b0 0x0
		6 0x16b4 0x0
		6 0x16a0 0x4
		6 0x16d0 0x0
		6 0x16d4 0x0
		6 0x16c0 0x4
		6 0x16f0 0x0
		6 0x16f4 0x0
		6 0x16e0 0x4
		6 0x1710 0x0
		6 0x1714 0x0
		6 0x1700 0x4
		6 0x1730 0x0
		6 0x1734 0x0
		6 0x1720 0x4
		6 0x1750 0x0
		6 0x1754 0x0
		6 0x1740 0x4
		6 0x1770 0x0
		6 0x1774 0x0
		6 0x1760 0x4
		6 0x1790 0x0
		6 0x1794 0x0
		6 0x1780 0x4
		6 0x17b0 0x0
		6 0x17b4 0x0
		6 0x17a0 0x4
		6 0x17d0 0x0
		6 0x17d4 0x0
		6 0x17c0 0x4
		6 0x17f0 0x0
		6 0x17f4 0x0
		6 0x1810 0x0
		6 0x1814 0x0
		6 0x17e0 0x4
		6 0x1800 0x5
		6 0x1830 0x0
		6 0x1834 0x0
		6 0x1850 0x0
		6 0x1854 0x0
		6 0x1820 0x4
		6 0x1840 0x5
		6 0x1870 0x0
		6 0x1874 0x0
		6 0x1890 0x0
		6 0x1894 0x0
		6 0x1860 0x4
		6 0x1880 0x5
		6 0x18b0 0x0
		6 0x18b4 0x0
		6 0x18d0 0x0
		6 0x18d4 0x0
		6 0x18a0 0x4
		6 0x18c0 0x5
		6 0x18f0 0x0
		6 0x18f4 0x0
		6 0x1910 0x0
		6 0x1914 0x0
		6 0x18e0 0x4
		6 0x1900 0x5
		6 0x1930 0x0
		6 0x1934 0x0
		6 0x1950 0x0
		6 0x1954 0x0
		6 0x1920 0x4
		6 0x1940 0x5
		6 0x1970 0x0
		6 0x1974 0x0
		6 0x1990 0x0
		6 0x1994 0x0
		6 0x1960 0x4
		6 0x1980 0x5
		6 0x19b0 0x0
		6 0x19b4 0x0
		6 0x19d0 0x0
		6 0x19d4 0x0
		6 0x19a0 0x4
		6 0x19c0 0x5
		6 0x19f0 0x0
		6 0x19f4 0x0
		6 0x1a10 0x0
		6 0x1a14 0x0
		6 0x19e0 0x4
		6 0x1a00 0x5
		6 0x1a30 0x0
		6 0x1a34 0x0
		6 0x1a50 0x0
		6 0x1a54 0x0
		6 0x1a20 0x4
		6 0x1a40 0x5
		6 0x1a70 0x0
		6 0x1a74 0x0
		6 0x1a60 0x4
		6 0x1a90 0x0
		6 0x1a94 0x0
		6 0x1a80 0x4
		6 0x1ab0 0x0
		6 0x1ab4 0x0
		6 0x1aa0 0x4
		6 0x1ad0 0x0
		6 0x1ad4 0x0
		6 0x1ac0 0x4
		6 0x1af0 0x0
		6 0x1af4 0x0
		6 0x1ae0 0x4
		6 0x1b10 0x0
		6 0x1b14 0x0
		6 0x1b00 0x4
		6 0x1b30 0x0
		6 0x1b34 0x0
		6 0x1b20 0x4
		6 0x1b50 0x0
		6 0x1b54 0x0
		6 0x1b40 0x4
		6 0x1b70 0x0
		6 0x1b74 0x0
		6 0x1b60 0x4
		6 0x1b90 0x0
		6 0x1b94 0x0
		6 0x1b80 0x4
		6 0x1bb0 0x0
		6 0x1bb4 0x0
		6 0x1bd0 0x0
		6 0x1bd4 0x0
		6 0x1ba0 0x4
		6 0x1bc0 0x5
		6 0x1bf0 0x0
		6 0x1bf4 0x0
		6 0x1c10 0x0
		6 0x1c14 0x0
		6 0x1be0 0x4
		6 0x1c00 0x5
		6 0x1c30 0x0
		6 0x1c34 0x0
		6 0x1c20 0x4
		6 0x1c50 0x0
		6 0x1c54 0x0
		6 0x1c40 0x4
		6 0x1c70 0x0
		6 0x1c74 0x0
		6 0x1c60 0x4
		6 0x1cb0 0x0
		6 0x1cb4 0x0
		6 0x1c90 0x0
		6 0x1c94 0x0
		6 0x1ca0 0x4
		6 0x1c80 0x5
		6 0x1cf0 0x0
		6 0x1cf4 0x0
		6 0x1cd0 0x0
		6 0x1cd4 0x0
		6 0x1ce0 0x4
		6 0x1cc0 0x5
		6 0x1d30 0x0
		6 0x1d34 0x0
		6 0x1d10 0x0
		6 0x1d14 0x0
		6 0x1d20 0x4
		6 0x1d00 0x5
		6 0x1d70 0x0
		6 0x1d74 0x0
		6 0x1d50 0x0
		6 0x1d54 0x0
		6 0x1d60 0x4
		6 0x1d40 0x5
		6 0x1db0 0x0
		6 0x1db4 0x0
		6 0x1d90 0x0
		6 0x1d94 0x0
		6 0x1da0 0x4
		6 0x1d80 0x5
		6 0x1df0 0x0
		6 0x1df4 0x0
		6 0x1dd0 0x0
		6 0x1dd4 0x0
		6 0x1de0 0x4
		6 0x1dc0 0x5
		6 0x1e30 0x0
		6 0x1e34 0x0
		6 0x1e10 0x0
		6 0x1e14 0x0
		6 0x1e20 0x4
		6 0x1e00 0x5
		6 0x1e70 0x0
		6 0x1e74 0x0
		6 0x1e50 0x0
		6 0x1e54 0x0
		6 0x1e60 0x4
		6 0x1e40 0x5
		6 0x1eb0 0x0
		6 0x1eb4 0x0
		6 0x1e90 0x0
		6 0x1e94 0x0
		6 0x1ea0 0x4
		6 0x1e80 0x5
		6 0x1ef0 0x0
		6 0x1ef4 0x0
		6 0x1ed0 0x0
		6 0x1ed4 0x0
		6 0x1ee0 0x4
		6 0x1ec0 0x5
		6 0x1f30 0x0
		6 0x1f34 0x0
		6 0x1f10 0x0
		6 0x1f14 0x0
		6 0x1f20 0x4
		6 0x1f00 0x5
		6 0x1f70 0x0
		6 0x1f74 0x0
		6 0x1f50 0x0
		6 0x1f54 0x0
		6 0x1f60 0x4
		6 0x1f40 0x5
		6 0x1fb0 0x0
		6 0x1fb4 0x0
		6 0x1f90 0x0
		6 0x1f94 0x0
		6 0x1fa0 0x4
		6 0x1f80 0x5
		6 0x1ff0 0x0
		6 0x1ff4 0x0
		6 0x1fd0 0x0
		6 0x1fd4 0x0
		6 0x1fe0 0x4
		6 0x1fc0 0x5
		6 0x2030 0x0
		6 0x2034 0x0
		6 0x2010 0x0
		6 0x2014 0x0
		6 0x2020 0x4
		6 0x2000 0x5
		6 0x2070 0x0
		6 0x2074 0x0
		6 0x2050 0x0
		6 0x2054 0x0
		6 0x2060 0x4
		6 0x2040 0x5
		6 0x20b0 0x0
		6 0x20b4 0x0
		6 0x2090 0x0
		6 0x2094 0x0
		6 0x20a0 0x4
		6 0x2080 0x5
		6 0x20f0 0x0
		6 0x20f4 0x0
		6 0x20d0 0x0
		6 0x20d4 0x0
		6 0x20e0 0x4
		6 0x20c0 0x5
		6 0x2130 0x0
		6 0x2134 0x0
		6 0x2110 0x0
		6 0x2114 0x0
		6 0x2120 0x4
		6 0x2100 0x5
		6 0x2170 0x0
		6 0x2174 0x0
		6 0x2150 0x0
		6 0x2154 0x0
		6 0x2160 0x4
		6 0x2140 0x5
		6 0x21b0 0x0
		6 0x21b4 0x0
		6 0x2190 0x0
		6 0x2194 0x0
		6 0x21a0 0x4
		6 0x2180 0x5
		6 0x21f0 0x0
		6 0x21f4 0x0
		6 0x21d0 0x0
		6 0x21d4 0x0
		6 0x21e0 0x4
		6 0x21c0 0x5
		6 0x2230 0x0
		6 0x2234 0x0
		6 0x2210 0x0
		6 0x2214 0x0
		6 0x2220 0x4
		6 0x2200 0x5
		6 0x2270 0x0
		6 0x2274 0x0
		6 0x2250 0x0
		6 0x2254 0x0
		6 0x2260 0x4
		6 0x2240 0x5
		6 0x22b0 0x0
		6 0x22b4 0x0
		6 0x2290 0x0
		6 0x2294 0x0
		6 0x22a0 0x4
		6 0x2280 0x5
		6 0x22f0 0x0
		6 0x22f4 0x0
		6 0x22d0 0x0
		6 0x22d4 0x0
		6 0x22e0 0x4
		6 0x22c0 0x5
		6 0x2330 0x0
		6 0x2334 0x0
		6 0x2310 0x0
		6 0x2314 0x0
		6 0x2320 0x4
		6 0x2300 0x5
		6 0x2370 0x0
		6 0x2374 0x0
		6 0x2350 0x0
		6 0x2354 0x0
		6 0x2360 0x4
		6 0x2340 0x5
		6 0x23b0 0x0
		6 0x23b4 0x0
		6 0x2390 0x0
		6 0x2394 0x0
		6 0x23a0 0x4
		6 0x2380 0x5
		6 0x23f0 0x0
		6 0x23f4 0x0
		6 0x23d0 0x0
		6 0x23d4 0x0
		6 0x23e0 0x4
		6 0x23c0 0x5
		6 0x2430 0x0
		6 0x2434 0x0
		6 0x2410 0x0
		6 0x2414 0x0
		6 0x2420 0x4
		6 0x2400 0x5
		6 0x2470 0x0
		6 0x2474 0x0
		6 0x2450 0x0
		6 0x2454 0x0
		6 0x2460 0x4
		6 0x2440 0x5
		6 0x2490 0x0
		6 0x2494 0x0
		6 0x2480 0x4
		6 0x24b0 0x0
		6 0x24b4 0x0
		6 0x24a0 0x4
		6 0x24d0 0x0
		6 0x24d4 0x0
		6 0x24c0 0x4
		6 0x24f0 0x0
		6 0x24f4 0x0
		6 0x24e0 0x4
		6 0x2510 0x0
		6 0x2514 0x0
		6 0x2500 0x4
		6 0x2530 0x0
		6 0x2534 0x0
		6 0x2520 0x4
		6 0x2550 0x0
		6 0x2554 0x0
		6 0x2540 0x4
		6 0x2570 0x0
		6 0x2574 0x0
		6 0x2560 0x4
		6 0x2590 0x0
		6 0x2594 0x0
		6 0x2580 0x4
		6 0x25b0 0x0
		6 0x25b4 0x0
		6 0x25a0 0x4
		6 0x25d0 0x0
		6 0x25d4 0x0
		6 0x25c0 0x4
		6 0x25f0 0x0
		6 0x25f4 0x0
		6 0x25e0 0x4
		6 0x2610 0x0
		6 0x2614 0x0
		6 0x2600 0x4
		6 0x2630 0x0
		6 0x2634 0x0
		6 0x2620 0x4
		6 0x2650 0x0
		6 0x2654 0x0
		6 0x2640 0x4
		6 0x2670 0x0
		6 0x2674 0x0
		6 0x2660 0x4
		6 0x2690 0x0
		6 0x2694 0x0
		6 0x26b0 0x0
		6 0x26b4 0x0
		6 0x2680 0x4
		6 0x26a0 0x5
		6 0x26d0 0x0
		6 0x26d4 0x0
		6 0x26f0 0x0
		6 0x26f4 0x0
		6 0x26c0 0x4
		6 0x26e0 0x5
		6 0x2710 0x0
		6 0x2714 0x0
		6 0x2730 0x0
		6 0x2734 0x0
		6 0x2700 0x4
		6 0x2720 0x5
		6 0x2750 0x0
		6 0x2754 0x0
		6 0x2770 0x0
		6 0x2774 0x0
		6 0x2740 0x4
		6 0x2760 0x5
		6 0x2790 0x0
		6 0x2794 0x0
		6 0x27b0 0x0
		6 0x27b4 0x0
		6 0x2780 0x4
		6 0x27a0 0x5
		6 0x27d0 0x0
		6 0x27d4 0x0
		6 0x27f0 0x0
		6 0x27f4 0x0
		6 0x27c0 0x4
		6 0x27e0 0x5
		6 0x2810 0x0
		6 0x2814 0x0
		6 0x2830 0x0
		6 0x2834 0x0
		6 0x2800 0x4
		6 0x2820 0x5
		6 0x2850 0x0
		6 0x2854 0x0
		6 0x2870 0x0
		6 0x2874 0x0
		6 0x2840 0x4
		6 0x2860 0x5
		6 0x2890 0x0
		6 0x2894 0x0
		6 0x28b0 0x0
		6 0x28b4 0x0
		6 0x2880 0x4
		6 0x28a0 0x5
		6 0x28d0 0x0
		6 0x28d4 0x0
		6 0x28f0 0x0
		6 0x28f4 0x0
		6 0x28c0 0x4
		6 0x28e0 0x5
		6 0x2910 0x0
		6 0x2914 0x0
		6 0x2900 0x4
		6 0x2930 0x0
		6 0x2934 0x0
		6 0x2920 0x4
		6 0x2950 0x0
		6 0x2954 0x0
		6 0x2940 0x4
		6 0x2970 0x0
		6 0x2974 0x0
		6 0x2960 0x4
		6 0x2990 0x0
		6 0x2994 0x0
		6 0x2980 0x4
		6 0x29b0 0x0
		6 0x29b4 0x0
		6 0x29a0 0x4
		6 0x29d0 0x0
		6 0x29d4 0x0
		6 0x29c0 0x4
		6 0x29f0 0x0
		6 0x29f4 0x0
		6 0x29e0 0x4
		6 0x2a10 0x0
		6 0x2a14 0x0
		6 0x2a00 0x4
		6 0x2a30 0x0
		6 0x2a34 0x0
		6 0x2a20 0x4
		6 0x2a50 0x0
		6 0x2a54 0x0
		6 0x2a40 0x4
		6 0x4110 0x0
		6 0x4114 0x0
		6 0x4130 0x0
		6 0x4134 0x0
		6 0x4100 0x4
		6 0x4120 0x5
		6 0x4150 0x0
		6 0x4154 0x0
		6 0x4170 0x0
		6 0x4174 0x0
		6 0x4140 0x4
		6 0x4160 0x5
		6 0x4190 0x0
		6 0x4194 0x0
		6 0x41b0 0x0
		6 0x41b4 0x0
		6 0x4180 0x4
		6 0x41a0 0x5
		6 0x41d0 0x0
		6 0x41d4 0x0
		6 0x41f0 0x0
		6 0x41f4 0x0
		6 0x41c0 0x4
		6 0x41e0 0x5
		6 0x4210 0x0
		6 0x4214 0x0
		6 0x4230 0x0
		6 0x4234 0x0
		6 0x4200 0x4
		6 0x4220 0x5
		6 0x4250 0x0
		6 0x4254 0x0
		6 0x4270 0x0
		6 0x4274 0x0
		6 0x4240 0x4
		6 0x4260 0x5
		6 0x4290 0x0
		6 0x4294 0x0
		6 0x42b0 0x0
		6 0x42b4 0x0
		6 0x4280 0x4
		6 0x42a0 0x5
		6 0x42d0 0x0
		6 0x42d4 0x0
		6 0x42f0 0x0
		6 0x42f4 0x0
		6 0x42c0 0x4
		6 0x42e0 0x5
		6 0x4310 0x0
		6 0x4314 0x0
		6 0x4330 0x0
		6 0x4334 0x0
		6 0x4300 0x4
		6 0x4320 0x5
		6 0x8110 0x0
		6 0x8114 0x0
		6 0x8130 0x0
		6 0x8134 0x0
		6 0x8100 0x4
		6 0x8120 0x5
		6 0x8150 0x0
		6 0x8154 0x0
		6 0x8170 0x0
		6 0x8174 0x0
		6 0x8140 0x4
		6 0x8160 0x5
		6 0x8190 0x0
		6 0x8194 0x0
		6 0x81b0 0x0
		6 0x81b4 0x0
		6 0x8180 0x4
		6 0x81a0 0x5
		6 0x81d0 0x0
		6 0x81d4 0x0
		6 0x81f0 0x0
		6 0x81f4 0x0
		6 0x81c0 0x4
		6 0x81e0 0x5
		6 0x8210 0x0
		6 0x8214 0x0
		6 0x8230 0x0
		6 0x8234 0x0
		6 0x8200 0x4
		6 0x8220 0x5
		6 0x8250 0x0
		6 0x8254 0x0
		6 0x8270 0x0
		6 0x8274 0x0
		6 0x8240 0x4
		6 0x8260 0x5
		6 0x8290 0x0
		6 0x8294 0x0
		6 0x82b0 0x0
		6 0x82b4 0x0
		6 0x8280 0x4
		6 0x82a0 0x5
		6 0x82d0 0x0
		6 0x82d4 0x0
		6 0x82f0 0x0
		6 0x82f4 0x0
		6 0x82c0 0x4
		6 0x82e0 0x5
		6 0x8310 0x0
		6 0x8314 0x0
		6 0x8330 0x0
		6 0x8334 0x0
		6 0x8300 0x4
		6 0x8320 0x5
		6 0x8910 0x0
		6 0x8914 0x0
		6 0x8930 0x0
		6 0x8934 0x0
		6 0x8900 0x4
		6 0x8920 0x5
		6 0x8950 0x0
		6 0x8954 0x0
		6 0x8970 0x0
		6 0x8974 0x0
		6 0x8940 0x4
		6 0x8960 0x5
		6 0x8990 0x0
		6 0x8994 0x0
		6 0x89b0 0x0
		6 0x89b4 0x0
		6 0x8980 0x4
		6 0x89a0 0x5
		6 0x89d0 0x0
		6 0x89d4 0x0
		6 0x89f0 0x0
		6 0x89f4 0x0
		6 0x89c0 0x4
		6 0x89e0 0x5
		6 0x8a10 0x0
		6 0x8a14 0x0
		6 0x8a30 0x0
		6 0x8a34 0x0
		6 0x8a00 0x4
		6 0x8a20 0x5
		6 0x8a50 0x0
		6 0x8a54 0x0
		6 0x8a70 0x0
		6 0x8a74 0x0
		6 0x8a40 0x4
		6 0x8a60 0x5
		6 0x8a90 0x0
		6 0x8a94 0x0
		6 0x8ab0 0x0
		6 0x8ab4 0x0
		6 0x8a80 0x4
		6 0x8aa0 0x5
		6 0x8ad0 0x0
		6 0x8ad4 0x0
		6 0x8af0 0x0
		6 0x8af4 0x0
		6 0x8ac0 0x4
		6 0x8ae0 0x5
		6 0x8b10 0x0
		6 0x8b14 0x0
		6 0x8b30 0x0
		6 0x8b34 0x0
		6 0x8b00 0x4
		6 0x8b20 0x5
		6 0x9110 0x0
		6 0x9114 0x0
		6 0x9130 0x0
		6 0x9134 0x0
		6 0x9100 0x4
		6 0x9120 0x5
		6 0x9150 0x0
		6 0x9154 0x0
		6 0x9170 0x0
		6 0x9174 0x0
		6 0x9140 0x4
		6 0x9160 0x5
		6 0x9190 0x0
		6 0x9194 0x0
		6 0x91b0 0x0
		6 0x91b4 0x0
		6 0x9180 0x4
		6 0x91a0 0x5
		6 0x91d0 0x0
		6 0x91d4 0x0
		6 0x91f0 0x0
		6 0x91f4 0x0
		6 0x91c0 0x4
		6 0x91e0 0x5
		6 0x9210 0x0
		6 0x9214 0x0
		6 0x9230 0x0
		6 0x9234 0x0
		6 0x9200 0x4
		6 0x9220 0x5
		6 0x9250 0x0
		6 0x9254 0x0
		6 0x9270 0x0
		6 0x9274 0x0
		6 0x9240 0x4
		6 0x9260 0x5
		6 0x9290 0x0
		6 0x9294 0x0
		6 0x92b0 0x0
		6 0x92b4 0x0
		6 0x9280 0x4
		6 0x92a0 0x5
		6 0x92d0 0x0
		6 0x92d4 0x0
		6 0x92f0 0x0
		6 0x92f4 0x0
		6 0x92c0 0x4
		6 0x92e0 0x5
		6 0x9310 0x0
		6 0x9314 0x0
		6 0x9330 0x0
		6 0x9334 0x0
		6 0x9300 0x4
		6 0x9320 0x5
		6 0x9910 0x0
		6 0x9914 0x0
		6 0x9930 0x0
		6 0x9934 0x0
		6 0x9900 0x4
		6 0x9920 0x5
		6 0x9950 0x0
		6 0x9954 0x0
		6 0x9970 0x0
		6 0x9974 0x0
		6 0x9940 0x4
		6 0x9960 0x5
		6 0x9990 0x0
		6 0x9994 0x0
		6 0x99b0 0x0
		6 0x99b4 0x0
		6 0x9980 0x4
		6 0x99a0 0x5
		6 0x99d0 0x0
		6 0x99d4 0x0
		6 0x99f0 0x0
		6 0x99f4 0x0
		6 0x99c0 0x4
		6 0x99e0 0x5
		6 0x9a10 0x0
		6 0x9a14 0x0
		6 0x9a30 0x0
		6 0x9a34 0x0
		6 0x9a00 0x4
		6 0x9a20 0x5
		6 0x9a50 0x0
		6 0x9a54 0x0
		6 0x9a70 0x0
		6 0x9a74 0x0
		6 0x9a40 0x4
		6 0x9a60 0x5
		6 0x9a90 0x0
		6 0x9a94 0x0
		6 0x9ab0 0x0
		6 0x9ab4 0x0
		6 0x9a80 0x4
		6 0x9aa0 0x5
		6 0x9ad0 0x0
		6 0x9ad4 0x0
		6 0x9af0 0x0
		6 0x9af4 0x0
		6 0x9ac0 0x4
		6 0x9ae0 0x5
		6 0x9b10 0x0
		6 0x9b14 0x0
		6 0x9b30 0x0
		6 0x9b34 0x0
		6 0x9b00 0x4
		6 0x9b20 0x5
		6 0xa110 0x0
		6 0xa114 0x0
		6 0xa130 0x0
		6 0xa134 0x0
		6 0xa100 0x4
		6 0xa120 0x5
		6 0xa150 0x0
		6 0xa154 0x0
		6 0xa170 0x0
		6 0xa174 0x0
		6 0xa140 0x4
		6 0xa160 0x5
		6 0xa190 0x0
		6 0xa194 0x0
		6 0xa1b0 0x0
		6 0xa1b4 0x0
		6 0xa180 0x4
		6 0xa1a0 0x5
		6 0xa1d0 0x0
		6 0xa1d4 0x0
		6 0xa1f0 0x0
		6 0xa1f4 0x0
		6 0xa1c0 0x4
		6 0xa1e0 0x5
		6 0xa210 0x0
		6 0xa214 0x0
		6 0xa230 0x0
		6 0xa234 0x0
		6 0xa200 0x4
		6 0xa220 0x5
		6 0xa250 0x0
		6 0xa254 0x0
		6 0xa270 0x0
		6 0xa274 0x0
		6 0xa240 0x4
		6 0xa260 0x5
		6 0xa290 0x0
		6 0xa294 0x0
		6 0xa2b0 0x0
		6 0xa2b4 0x0
		6 0xa280 0x4
		6 0xa2a0 0x5
		6 0xa2d0 0x0
		6 0xa2d4 0x0
		6 0xa2f0 0x0
		6 0xa2f4 0x0
		6 0xa2c0 0x4
		6 0xa2e0 0x5
		6 0xa310 0x0
		6 0xa314 0x0
		6 0xa330 0x0
		6 0xa334 0x0
		6 0xa300 0x4
		6 0xa320 0x5
		6 0xa910 0x0
		6 0xa914 0x0
		6 0xa930 0x0
		6 0xa934 0x0
		6 0xa900 0x4
		6 0xa920 0x5
		6 0xa950 0x0
		6 0xa954 0x0
		6 0xa970 0x0
		6 0xa974 0x0
		6 0xa940 0x4
		6 0xa960 0x5
		6 0xa990 0x0
		6 0xa994 0x0
		6 0xa9b0 0x0
		6 0xa9b4 0x0
		6 0xa980 0x4
		6 0xa9a0 0x5
		6 0xa9d0 0x0
		6 0xa9d4 0x0
		6 0xa9f0 0x0
		6 0xa9f4 0x0
		6 0xa9c0 0x4
		6 0xa9e0 0x5
		6 0xaa10 0x0
		6 0xaa14 0x0
		6 0xaa30 0x0
		6 0xaa34 0x0
		6 0xaa00 0x4
		6 0xaa20 0x5
		6 0xaa50 0x0
		6 0xaa54 0x0
		6 0xaa70 0x0
		6 0xaa74 0x0
		6 0xaa40 0x4
		6 0xaa60 0x5
		6 0xaa90 0x0
		6 0xaa94 0x0
		6 0xaab0 0x0
		6 0xaab4 0x0
		6 0xaa80 0x4
		6 0xaaa0 0x5
		6 0xaad0 0x0
		6 0xaad4 0x0
		6 0xaaf0 0x0
		6 0xaaf4 0x0
		6 0xaac0 0x4
		6 0xaae0 0x5
		6 0xab10 0x0
		6 0xab14 0x0
		6 0xab30 0x0
		6 0xab34 0x0
		6 0xab00 0x4
		6 0xab20 0x5
		6 0xb110 0x0
		6 0xb114 0x0
		6 0xb130 0x0
		6 0xb134 0x0
		6 0xb100 0x4
		6 0xb120 0x5
		6 0xb150 0x0
		6 0xb154 0x0
		6 0xb170 0x0
		6 0xb174 0x0
		6 0xb140 0x4
		6 0xb160 0x5
		6 0xb190 0x0
		6 0xb194 0x0
		6 0xb1b0 0x0
		6 0xb1b4 0x0
		6 0xb180 0x4
		6 0xb1a0 0x5
		6 0xb1d0 0x0
		6 0xb1d4 0x0
		6 0xb1f0 0x0
		6 0xb1f4 0x0
		6 0xb1c0 0x4
		6 0xb1e0 0x5
		6 0xb210 0x0
		6 0xb214 0x0
		6 0xb230 0x0
		6 0xb234 0x0
		6 0xb200 0x4
		6 0xb220 0x5
		6 0xb250 0x0
		6 0xb254 0x0
		6 0xb270 0x0
		6 0xb274 0x0
		6 0xb240 0x4
		6 0xb260 0x5
		6 0xb290 0x0
		6 0xb294 0x0
		6 0xb2b0 0x0
		6 0xb2b4 0x0
		6 0xb280 0x4
		6 0xb2a0 0x5
		6 0xb2d0 0x0
		6 0xb2d4 0x0
		6 0xb2f0 0x0
		6 0xb2f4 0x0
		6 0xb2c0 0x4
		6 0xb2e0 0x5
		6 0xb310 0x0
		6 0xb314 0x0
		6 0xb330 0x0
		6 0xb334 0x0
		6 0xb300 0x4
		6 0xb320 0x5
		6 0xc110 0x0
		6 0xc114 0x0
		6 0xc100 0x4
		6 0xc130 0x0
		6 0xc134 0x0
		6 0xc120 0x4
		6 0xc150 0x0
		6 0xc154 0x0
		6 0xc140 0x4
		6 0xc170 0x0
		6 0xc174 0x0
		6 0xc160 0x4
		6 0xc190 0x0
		6 0xc194 0x0
		6 0xc180 0x4
		6 0xc1b0 0x0
		6 0xc1b4 0x0
		6 0xc1a0 0x4
		6 0xc1d0 0x0
		6 0xc1d4 0x0
		6 0xc1c0 0x4
		6 0xc1f0 0x0
		6 0xc1f4 0x0
		6 0xc1e0 0x4
		6 0xc210 0x0
		6 0xc214 0x0
		6 0xc200 0x4
		6 0xc230 0x0
		6 0xc234 0x0
		6 0xc220 0x4
		6 0xc250 0x0
		6 0xc254 0x0
		6 0xc240 0x4
		6 0xc270 0x0
		6 0xc274 0x0
		6 0xc260 0x4
		6 0xc290 0x0
		6 0xc294 0x0
		6 0xc280 0x4
		6 0xc2b0 0x0
		6 0xc2b4 0x0
		6 0xc2a0 0x4
		6 0xc2d0 0x0
		6 0xc2d4 0x0
		6 0xc2c0 0x4
		6 0xc2f0 0x0
		6 0xc2f4 0x0
		6 0xc2e0 0x4
		6 0xc310 0x0
		6 0xc314 0x0
		6 0xc300 0x4
		6 0xc330 0x0
		6 0xc334 0x0
		6 0xc320 0x4
		6 0xc350 0x0
		6 0xc354 0x0
		6 0xc340 0x4
		6 0xc370 0x0
		6 0xc374 0x0
		6 0xc360 0x4
		6 0xc390 0x0
		6 0xc394 0x0
		6 0xc380 0x4
		6 0xc3b0 0x0
		6 0xc3b4 0x0
		6 0xc3a0 0x4
		6 0xc3d0 0x0
		6 0xc3d4 0x0
		6 0xc3c0 0x4
		6 0xc3f0 0x0
		6 0xc3f4 0x0
		6 0xc3e0 0x4
		6 0xc410 0x0
		6 0xc414 0x0
		6 0xc400 0x4
		6 0xc430 0x0
		6 0xc434 0x0
		6 0xc420 0x4
		6 0xc450 0x0
		6 0xc454 0x0
		6 0xc440 0x4
		6 0xc470 0x0
		6 0xc474 0x0
		6 0xc460 0x4
		6 0xc490 0x0
		6 0xc494 0x0
		6 0xc480 0x4
		6 0xc4b0 0x0
		6 0xc4b4 0x0
		6 0xc4a0 0x4
		6 0xc4d0 0x0
		6 0xc4d4 0x0
		6 0xc4c0 0x4
		6 0xc4f0 0x0
		6 0xc4f4 0x0
		6 0xc4e0 0x4
		6 0xc510 0x0
		6 0xc514 0x0
		6 0xc500 0x4
		6 0xc530 0x0
		6 0xc534 0x0
		6 0xc520 0x4
		6 0xc550 0x0
		6 0xc554 0x0
		6 0xc540 0x4
		6 0xc570 0x0
		6 0xc574 0x0
		6 0xc560 0x4
		6 0xc590 0x0
		6 0xc594 0x0
		6 0xc580 0x4
		6 0xc5b0 0x0
		6 0xc5b4 0x0
		6 0xc5a0 0x4
		6 0xc5d0 0x0
		6 0xc5d4 0x0
		6 0xc5c0 0x4
		6 0xc5f0 0x0
		6 0xc5f4 0x0
		6 0xc5e0 0x4
		6 0xc610 0x0
		6 0xc614 0x0
		6 0xc600 0x4
		6 0xc630 0x0
		6 0xc634 0x0
		6 0xc620 0x4
		6 0xc650 0x0
		6 0xc654 0x0
		6 0xc640 0x4
		6 0xc670 0x0
		6 0xc674 0x0
		6 0xc660 0x4
		6 0xc690 0x0
		6 0xc694 0x0
		6 0xc680 0x4
		6 0xc6b0 0x0
		6 0xc6b4 0x0
		6 0xc6a0 0x4
		6 0xc6d0 0x0
		6 0xc6d4 0x0
		6 0xc6c0 0x4
		6 0xc6f0 0x0
		6 0xc6f4 0x0
		6 0xc6e0 0x4
		7 0x108 0x0
		7 0x10c 0x0
		7 0x100 0x1
		7 0x118 0x0
		7 0x11c 0x0
		7 0x110 0x1
		7 0x128 0x0
		7 0x12c 0x0
		7 0x120 0x1
		7 0x138 0x0
		7 0x13c 0x0
		7 0x130 0x1
		7 0x148 0x0
		7 0x14c 0x0
		7 0x140 0x1
		7 0x158 0x0
		7 0x15c 0x0
		7 0x150 0x1
		7 0x168 0x0
		7 0x16c 0x0
		7 0x160 0x1
		7 0x178 0x0
		7 0x17c 0x0
		7 0x170 0x1
		7 0x188 0x0
		7 0x18c 0x0
		7 0x180 0x1
		7 0x198 0x0
		7 0x19c 0x0
		7 0x190 0x1
		7 0x1a8 0x0
		7 0x1ac 0x0
		7 0x1a0 0x1
		8 0x2110 0x0
		8 0x2114 0x0
		8 0x2100 0x4
		8 0x2130 0x0
		8 0x2134 0x0
		8 0x2120 0x4
		8 0x2150 0x0
		8 0x2154 0x0
		8 0x2140 0x4
		8 0x2170 0x0
		8 0x2174 0x0
		8 0x2160 0x4
		8 0x2190 0x0
		8 0x2194 0x0
		8 0x2180 0x4
		8 0x21b0 0x0
		8 0x21b4 0x0
		8 0x21a0 0x4
		8 0x21d0 0x0
		8 0x21d4 0x0
		8 0x21c0 0x4
		8 0x21f0 0x0
		8 0x21f4 0x0
		8 0x21e0 0x4
		8 0x2210 0x0
		8 0x2214 0x0
		8 0x2200 0x4
		8 0x2230 0x0
		8 0x2234 0x0
		8 0x2220 0x4
		8 0x2250 0x0
		8 0x2254 0x0
		8 0x2240 0x4
		8 0x2270 0x0
		8 0x2274 0x0
		8 0x2260 0x4
		8 0x2290 0x0
		8 0x2294 0x0
		8 0x2280 0x4
		8 0x22b0 0x0
		8 0x22b4 0x0
		8 0x22a0 0x4
		8 0x22d0 0x0
		8 0x22d4 0x0
		8 0x22c0 0x4
		8 0x22f0 0x0
		8 0x22f4 0x0
		8 0x22e0 0x4
		8 0x2310 0x0
		8 0x2314 0x0
		8 0x2300 0x4
		8 0x2330 0x0
		8 0x2334 0x0
		8 0x2320 0x4
		8 0x2350 0x0
		8 0x2354 0x0
		8 0x2340 0x4
		8 0x2370 0x0
		8 0x2374 0x0
		8 0x2360 0x4
		8 0x2390 0x0
		8 0x2394 0x0
		8 0x2380 0x4
		8 0x23b0 0x0
		8 0x23b4 0x0
		8 0x23a0 0x4
		8 0x23d0 0x0
		8 0x23d4 0x0
		8 0x23c0 0x4
		8 0x23f0 0x0
		8 0x23f4 0x0
		8 0x23e0 0x4
		8 0x2410 0x0
		8 0x2414 0x0
		8 0x2400 0x4
		8 0x2430 0x0
		8 0x2434 0x0
		8 0x2420 0x4
		8 0x2450 0x0
		8 0x2454 0x0
		8 0x2440 0x4
		8 0x2470 0x0
		8 0x2474 0x0
		8 0x2460 0x4
		8 0x2490 0x0
		8 0x2494 0x0
		8 0x2480 0x4
		8 0x24b0 0x0
		8 0x24b4 0x0
		8 0x24a0 0x4
		8 0x24d0 0x0
		8 0x24d4 0x0
		8 0x24c0 0x4
		8 0x24f0 0x0
		8 0x24f4 0x0
		8 0x24e0 0x4
		8 0x2510 0x0
		8 0x2514 0x0
		8 0x2500 0x4
		8 0x2530 0x0
		8 0x2534 0x0
		8 0x2520 0x4
		8 0x2550 0x0
		8 0x2554 0x0
		8 0x2540 0x4
		8 0x2570 0x0
		8 0x2574 0x0
		8 0x2560 0x4
		8 0x2590 0x0
		8 0x2594 0x0
		8 0x2580 0x4
		10 0x1b70 0x0
		10 0x1b74 0x0
		10 0x1b90 0x0
		10 0x1b94 0x0
		10 0x1b60 0x4
		10 0x1b80 0x5
		10 0x1bb0 0x0
		10 0x1bb4 0x0
		10 0x1bd0 0x0
		10 0x1bd4 0x0
		10 0x1ba0 0x4
		10 0x1bc0 0x5
		10 0x1bf0 0x0
		10 0x1bf4 0x0
		10 0x1c10 0x0
		10 0x1c14 0x0
		10 0x1be0 0x4
		10 0x1c00 0x5
		10 0x1c30 0x0
		10 0x1c34 0x0
		10 0x1c50 0x0
		10 0x1c54 0x0
		10 0x1c20 0x4
		10 0x1c40 0x5
		10 0x1c70 0x0
		10 0x1c74 0x0
		10 0x1c90 0x0
		10 0x1c94 0x0
		10 0x1c60 0x4
		10 0x1c80 0x5
		10 0x1cb0 0x0
		10 0x1cb4 0x0
		10 0x1cd0 0x0
		10 0x1cd4 0x0
		10 0x1ca0 0x4
		10 0x1cc0 0x5
		10 0x1cf0 0x0
		10 0x1cf4 0x0
		10 0x1d10 0x0
		10 0x1d14 0x0
		10 0x1ce0 0x4
		10 0x1d00 0x5
		10 0x1d30 0x0
		10 0x1d34 0x0
		10 0x1d50 0x0
		10 0x1d54 0x0
		10 0x1d20 0x4
		10 0x1d40 0x5
		10 0x1d70 0x0
		10 0x1d74 0x0
		10 0x1d90 0x0
		10 0x1d94 0x0
		10 0x1d60 0x4
		10 0x1d80 0x5
		10 0x1dd0 0x0
		10 0x1dd4 0x0
		10 0x1db0 0x0
		10 0x1db4 0x0
		10 0x1dc0 0x4
		10 0x1da0 0x5
		10 0x1df0 0x0
		10 0x1df4 0x0
		10 0x1e10 0x0
		10 0x1e14 0x0
		10 0x1de0 0x4
		10 0x1e00 0x5
		10 0x1e30 0x0
		10 0x1e34 0x0
		10 0x1e50 0x0
		10 0x1e54 0x0
		10 0x1e20 0x4
		10 0x1e40 0x5
		10 0x1e70 0x0
		10 0x1e74 0x0
		10 0x1e60 0x4
		10 0x1e90 0x0
		10 0x1e94 0x0
		10 0x1e80 0x4
		10 0x1eb0 0x0
		10 0x1eb4 0x0
		10 0x1ea0 0x4
		10 0x1ed0 0x0
		10 0x1ed4 0x0
		10 0x1ec0 0x4
		10 0x1ef0 0x0
		10 0x1ef4 0x0
		10 0x1ee0 0x4
		10 0x1f10 0x0
		10 0x1f14 0x0
		10 0x1f00 0x4
		10 0x1f30 0x0
		10 0x1f34 0x0
		10 0x1f20 0x4
		10 0x1f50 0x0
		10 0x1f54 0x0
		10 0x1f40 0x4
		10 0x1f70 0x0
		10 0x1f74 0x0
		10 0x1f60 0x4
		10 0x1f90 0x0
		10 0x1f94 0x0
		10 0x1f80 0x4
		10 0x1fb0 0x0
		10 0x1fb4 0x0
		10 0x1fa0 0x4
		10 0x1fd0 0x0
		10 0x1fd4 0x0
		10 0x1fc0 0x4
		10 0x1ff0 0x0
		10 0x1ff4 0x0
		10 0x1fe0 0x4
		10 0x2010 0x0
		10 0x2014 0x0
		10 0x2000 0x4
		10 0x2030 0x0
		10 0x2034 0x0
		10 0x2020 0x4
		10 0x2050 0x0
		10 0x2054 0x0
		10 0x2040 0x4
		10 0x2070 0x0
		10 0x2074 0x0
		10 0x2060 0x4
		10 0x2090 0x0
		10 0x2094 0x0
		10 0x2080 0x4
		10 0x20b0 0x0
		10 0x20b4 0x0
		10 0x20a0 0x4
		10 0x8110 0x0
		10 0x8114 0x0
		10 0x8130 0x0
		10 0x8134 0x0
		10 0x8100 0x4
		10 0x8120 0x5
		10 0x8150 0x0
		10 0x8154 0x0
		10 0x8170 0x0
		10 0x8174 0x0
		10 0x8140 0x4
		10 0x8160 0x5
		10 0x8190 0x0
		10 0x8194 0x0
		10 0x81b0 0x0
		10 0x81b4 0x0
		10 0x8180 0x4
		10 0x81a0 0x5
		10 0x81d0 0x0
		10 0x81d4 0x0
		10 0x81f0 0x0
		10 0x81f4 0x0
		10 0x81c0 0x4
		10 0x81e0 0x5
		10 0x8210 0x0
		10 0x8214 0x0
		10 0x8230 0x0
		10 0x8234 0x0
		10 0x8200 0x4
		10 0x8220 0x5
		10 0x8250 0x0
		10 0x8254 0x0
		10 0x8270 0x0
		10 0x8274 0x0
		10 0x8240 0x4
		10 0x8260 0x5
		10 0x8290 0x0
		10 0x8294 0x0
		10 0x82b0 0x0
		10 0x82b4 0x0
		10 0x8280 0x4
		10 0x82a0 0x5
		10 0x82d0 0x0
		10 0x82d4 0x0
		10 0x82f0 0x0
		10 0x82f4 0x0
		10 0x82c0 0x4
		10 0x82e0 0x5
		10 0x8310 0x0
		10 0x8314 0x0
		10 0x8330 0x0
		10 0x8334 0x0
		10 0x8300 0x4
		10 0x8320 0x5
		10 0x8910 0x0
		10 0x8914 0x0
		10 0x8930 0x0
		10 0x8934 0x0
		10 0x8900 0x4
		10 0x8920 0x5
		10 0x8950 0x0
		10 0x8954 0x0
		10 0x8970 0x0
		10 0x8974 0x0
		10 0x8940 0x4
		10 0x8960 0x5
		10 0x8990 0x0
		10 0x8994 0x0
		10 0x89b0 0x0
		10 0x89b4 0x0
		10 0x8980 0x4
		10 0x89a0 0x5
		10 0x89d0 0x0
		10 0x89d4 0x0
		10 0x89f0 0x0
		10 0x89f4 0x0
		10 0x89c0 0x4
		10 0x89e0 0x5
		10 0x8a10 0x0
		10 0x8a14 0x0
		10 0x8a30 0x0
		10 0x8a34 0x0
		10 0x8a00 0x4
		10 0x8a20 0x5
		10 0x8a50 0x0
		10 0x8a54 0x0
		10 0x8a70 0x0
		10 0x8a74 0x0
		10 0x8a40 0x4
		10 0x8a60 0x5
		10 0x8a90 0x0
		10 0x8a94 0x0
		10 0x8ab0 0x0
		10 0x8ab4 0x0
		10 0x8a80 0x4
		10 0x8aa0 0x5
		10 0x8ad0 0x0
		10 0x8ad4 0x0
		10 0x8af0 0x0
		10 0x8af4 0x0
		10 0x8ac0 0x4
		10 0x8ae0 0x5
		10 0x8b10 0x0
		10 0x8b14 0x0
		10 0x8b30 0x0
		10 0x8b34 0x0
		10 0x8b00 0x4
		10 0x8b20 0x5
		10 0x9110 0x0
		10 0x9114 0x0
		10 0x9130 0x0
		10 0x9134 0x0
		10 0x9100 0x4
		10 0x9120 0x5
		10 0x9150 0x0
		10 0x9154 0x0
		10 0x9170 0x0
		10 0x9174 0x0
		10 0x9140 0x4
		10 0x9160 0x5
		10 0x9190 0x0
		10 0x9194 0x0
		10 0x91b0 0x0
		10 0x91b4 0x0
		10 0x9180 0x4
		10 0x91a0 0x5
		10 0x91d0 0x0
		10 0x91d4 0x0
		10 0x91f0 0x0
		10 0x91f4 0x0
		10 0x91c0 0x4
		10 0x91e0 0x5
		10 0x9210 0x0
		10 0x9214 0x0
		10 0x9230 0x0
		10 0x9234 0x0
		10 0x9200 0x4
		10 0x9220 0x5
		10 0x9250 0x0
		10 0x9254 0x0
		10 0x9270 0x0
		10 0x9274 0x0
		10 0x9240 0x4
		10 0x9260 0x5
		10 0x9290 0x0
		10 0x9294 0x0
		10 0x92b0 0x0
		10 0x92b4 0x0
		10 0x9280 0x4
		10 0x92a0 0x5
		10 0x92d0 0x0
		10 0x92d4 0x0
		10 0x92f0 0x0
		10 0x92f4 0x0
		10 0x92c0 0x4
		10 0x92e0 0x5
		10 0x9310 0x0
		10 0x9314 0x0
		10 0x9330 0x0
		10 0x9334 0x0
		10 0x9300 0x4
		10 0x9320 0x5
		10 0x9910 0x0
		10 0x9914 0x0
		10 0x9930 0x0
		10 0x9934 0x0
		10 0x9900 0x4
		10 0x9920 0x5
		10 0x9950 0x0
		10 0x9954 0x0
		10 0x9970 0x0
		10 0x9974 0x0
		10 0x9940 0x4
		10 0x9960 0x5
		10 0x9990 0x0
		10 0x9994 0x0
		10 0x99b0 0x0
		10 0x99b4 0x0
		10 0x9980 0x4
		10 0x99a0 0x5
		10 0x99d0 0x0
		10 0x99d4 0x0
		10 0x99f0 0x0
		10 0x99f4 0x0
		10 0x99c0 0x4
		10 0x99e0 0x5
		10 0x9a10 0x0
		10 0x9a14 0x0
		10 0x9a30 0x0
		10 0x9a34 0x0
		10 0x9a00 0x4
		10 0x9a20 0x5
		10 0x9a50 0x0
		10 0x9a54 0x0
		10 0x9a70 0x0
		10 0x9a74 0x0
		10 0x9a40 0x4
		10 0x9a60 0x5
		10 0x9a90 0x0
		10 0x9a94 0x0
		10 0x9ab0 0x0
		10 0x9ab4 0x0
		10 0x9a80 0x4
		10 0x9aa0 0x5
		10 0x9ad0 0x0
		10 0x9ad4 0x0
		10 0x9af0 0x0
		10 0x9af4 0x0
		10 0x9ac0 0x4
		10 0x9ae0 0x5
		10 0x9b10 0x0
		10 0x9b14 0x0
		10 0x9b30 0x0
		10 0x9b34 0x0
		10 0x9b00 0x4
		10 0x9b20 0x5
		10 0xa110 0x0
		10 0xa114 0x0
		10 0xa130 0x0
		10 0xa134 0x0
		10 0xa100 0x4
		10 0xa120 0x5
		10 0xa150 0x0
		10 0xa154 0x0
		10 0xa170 0x0
		10 0xa174 0x0
		10 0xa140 0x4
		10 0xa160 0x5
		10 0xa190 0x0
		10 0xa194 0x0
		10 0xa1b0 0x0
		10 0xa1b4 0x0
		10 0xa180 0x4
		10 0xa1a0 0x5
		10 0xa1d0 0x0
		10 0xa1d4 0x0
		10 0xa1f0 0x0
		10 0xa1f4 0x0
		10 0xa1c0 0x4
		10 0xa1e0 0x5
		10 0xa210 0x0
		10 0xa214 0x0
		10 0xa230 0x0
		10 0xa234 0x0
		10 0xa200 0x4
		10 0xa220 0x5
		10 0xa250 0x0
		10 0xa254 0x0
		10 0xa270 0x0
		10 0xa274 0x0
		10 0xa240 0x4
		10 0xa260 0x5
		10 0xa290 0x0
		10 0xa294 0x0
		10 0xa2b0 0x0
		10 0xa2b4 0x0
		10 0xa280 0x4
		10 0xa2a0 0x5
		10 0xa2d0 0x0
		10 0xa2d4 0x0
		10 0xa2f0 0x0
		10 0xa2f4 0x0
		10 0xa2c0 0x4
		10 0xa2e0 0x5
		10 0xa310 0x0
		10 0xa314 0x0
		10 0xa330 0x0
		10 0xa334 0x0
		10 0xa300 0x4
		10 0xa320 0x5
		10 0xa910 0x0
		10 0xa914 0x0
		10 0xa930 0x0
		10 0xa934 0x0
		10 0xa900 0x4
		10 0xa920 0x5
		10 0xa950 0x0
		10 0xa954 0x0
		10 0xa970 0x0
		10 0xa974 0x0
		10 0xa940 0x4
		10 0xa960 0x5
		10 0xa990 0x0
		10 0xa994 0x0
		10 0xa9b0 0x0
		10 0xa9b4 0x0
		10 0xa980 0x4
		10 0xa9a0 0x5
		10 0xa9d0 0x0
		10 0xa9d4 0x0
		10 0xa9f0 0x0
		10 0xa9f4 0x0
		10 0xa9c0 0x4
		10 0xa9e0 0x5
		10 0xaa10 0x0
		10 0xaa14 0x0
		10 0xaa30 0x0
		10 0xaa34 0x0
		10 0xaa00 0x4
		10 0xaa20 0x5
		10 0xaa50 0x0
		10 0xaa54 0x0
		10 0xaa70 0x0
		10 0xaa74 0x0
		10 0xaa40 0x4
		10 0xaa60 0x5
		10 0xaa90 0x0
		10 0xaa94 0x0
		10 0xaab0 0x0
		10 0xaab4 0x0
		10 0xaa80 0x4
		10 0xaaa0 0x5
		10 0xaad0 0x0
		10 0xaad4 0x0
		10 0xaaf0 0x0
		10 0xaaf4 0x0
		10 0xaac0 0x4
		10 0xaae0 0x5
		10 0xab10 0x0
		10 0xab14 0x0
		10 0xab30 0x0
		10 0xab34 0x0
		10 0xab00 0x4
		10 0xab20 0x5
		10 0xb110 0x0
		10 0xb114 0x0
		10 0xb130 0x0
		10 0xb134 0x0
		10 0xb100 0x4
		10 0xb120 0x5
		10 0xb150 0x0
		10 0xb154 0x0
		10 0xb170 0x0
		10 0xb174 0x0
		10 0xb140 0x4
		10 0xb160 0x5
		10 0xb190 0x0
		10 0xb194 0x0
		10 0xb1b0 0x0
		10 0xb1b4 0x0
		10 0xb180 0x4
		10 0xb1a0 0x5
		10 0xb1d0 0x0
		10 0xb1d4 0x0
		10 0xb1f0 0x0
		10 0xb1f4 0x0
		10 0xb1c0 0x4
		10 0xb1e0 0x5
		10 0xb210 0x0
		10 0xb214 0x0
		10 0xb230 0x0
		10 0xb234 0x0
		10 0xb200 0x4
		10 0xb220 0x5
		10 0xb250 0x0
		10 0xb254 0x0
		10 0xb270 0x0
		10 0xb274 0x0
		10 0xb240 0x4
		10 0xb260 0x5
		10 0xb290 0x0
		10 0xb294 0x0
		10 0xb2b0 0x0
		10 0xb2b4 0x0
		10 0xb280 0x4
		10 0xb2a0 0x5
		10 0xb2d0 0x0
		10 0xb2d4 0x0
		10 0xb2f0 0x0
		10 0xb2f4 0x0
		10 0xb2c0 0x4
		10 0xb2e0 0x5
		10 0xb310 0x0
		10 0xb314 0x0
		10 0xb330 0x0
		10 0xb334 0x0
		10 0xb300 0x4
		10 0xb320 0x5
		10 0xc110 0x0
		10 0xc114 0x0
		10 0xc130 0x0
		10 0xc134 0x0
		10 0xc100 0x4
		10 0xc120 0x5
		10 0xc150 0x0
		10 0xc154 0x0
		10 0xc170 0x0
		10 0xc174 0x0
		10 0xc140 0x4
		10 0xc160 0x5
		10 0xc190 0x0
		10 0xc194 0x0
		10 0xc1b0 0x0
		10 0xc1b4 0x0
		10 0xc180 0x4
		10 0xc1a0 0x5
		10 0xc1d0 0x0
		10 0xc1d4 0x0
		10 0xc1f0 0x0
		10 0xc1f4 0x0
		10 0xc1c0 0x4
		10 0xc1e0 0x5
		10 0xc210 0x0
		10 0xc214 0x0
		10 0xc230 0x0
		10 0xc234 0x0
		10 0xc200 0x4
		10 0xc220 0x5
		10 0xc250 0x0
		10 0xc254 0x0
		10 0xc270 0x0
		10 0xc274 0x0
		10 0xc240 0x4
		10 0xc260 0x5
		10 0xc290 0x0
		10 0xc294 0x0
		10 0xc2b0 0x0
		10 0xc2b4 0x0
		10 0xc280 0x4
		10 0xc2a0 0x5
		10 0xc2d0 0x0
		10 0xc2d4 0x0
		10 0xc2f0 0x0
		10 0xc2f4 0x0
		10 0xc2c0 0x4
		10 0xc2e0 0x5
		10 0xc310 0x0
		10 0xc314 0x0
		10 0xc330 0x0
		10 0xc334 0x0
		10 0xc300 0x4
		10 0xc320 0x5
		10 0xd110 0x0
		10 0xd114 0x0
		10 0xd130 0x0
		10 0xd134 0x0
		10 0xd100 0x4
		10 0xd120 0x5
		10 0xd150 0x0
		10 0xd154 0x0
		10 0xd170 0x0
		10 0xd174 0x0
		10 0xd140 0x4
		10 0xd160 0x5
		10 0xd190 0x0
		10 0xd194 0x0
		10 0xd1b0 0x0
		10 0xd1b4 0x0
		10 0xd180 0x4
		10 0xd1a0 0x5
		10 0xd1d0 0x0
		10 0xd1d4 0x0
		10 0xd1f0 0x0
		10 0xd1f4 0x0
		10 0xd1c0 0x4
		10 0xd1e0 0x5
		10 0xd210 0x0
		10 0xd214 0x0
		10 0xd230 0x0
		10 0xd234 0x0
		10 0xd200 0x4
		10 0xd220 0x5
		10 0xd250 0x0
		10 0xd254 0x0
		10 0xd270 0x0
		10 0xd274 0x0
		10 0xd240 0x4
		10 0xd260 0x5
		10 0xd290 0x0
		10 0xd294 0x0
		10 0xd2b0 0x0
		10 0xd2b4 0x0
		10 0xd280 0x4
		10 0xd2a0 0x5
		10 0xd2d0 0x0
		10 0xd2d4 0x0
		10 0xd2f0 0x0
		10 0xd2f4 0x0
		10 0xd2c0 0x4
		10 0xd2e0 0x5
		10 0xd310 0x0
		10 0xd314 0x0
		10 0xd330 0x0
		10 0xd334 0x0
		10 0xd300 0x4
		10 0xd320 0x5
		10 0xe110 0x0
		10 0xe114 0x0
		10 0xe130 0x0
		10 0xe134 0x0
		10 0xe100 0x4
		10 0xe120 0x5
		10 0xe150 0x0
		10 0xe154 0x0
		10 0xe170 0x0
		10 0xe174 0x0
		10 0xe140 0x4
		10 0xe160 0x5
		10 0xe190 0x0
		10 0xe194 0x0
		10 0xe1b0 0x0
		10 0xe1b4 0x0
		10 0xe180 0x4
		10 0xe1a0 0x5
		10 0xe1d0 0x0
		10 0xe1d4 0x0
		10 0xe1f0 0x0
		10 0xe1f4 0x0
		10 0xe1c0 0x4
		10 0xe1e0 0x5
		10 0xe210 0x0
		10 0xe214 0x0
		10 0xe230 0x0
		10 0xe234 0x0
		10 0xe200 0x4
		10 0xe220 0x5
		10 0xe250 0x0
		10 0xe254 0x0
		10 0xe270 0x0
		10 0xe274 0x0
		10 0xe240 0x4
		10 0xe260 0x5
		10 0xe290 0x0
		10 0xe294 0x0
		10 0xe2b0 0x0
		10 0xe2b4 0x0
		10 0xe280 0x4
		10 0xe2a0 0x5
		10 0xe2d0 0x0
		10 0xe2d4 0x0
		10 0xe2f0 0x0
		10 0xe2f4 0x0
		10 0xe2c0 0x4
		10 0xe2e0 0x5
		10 0xe310 0x0
		10 0xe314 0x0
		10 0xe330 0x0
		10 0xe334 0x0
		10 0xe300 0x4
		10 0xe320 0x5
		6 0x0 0x30001
		6 0x4000 0x1
		6 0x8000 0x1
		6 0x8800 0x1
		6 0x9000 0x1
		6 0x9800 0x1
		6 0xa000 0x1
		6 0xa800 0x1
		6 0xb000 0x1
		6 0xc000 0x1
		7 0x0 0x1
		8 0x0 0x30001
		8 0x2000 0x1
		10 0x0 0x30001
		10 0x8000 0x1
		10 0x8800 0x1
		10 0x9000 0x1
		10 0x9800 0x1
		10 0xa000 0x1
		10 0xa800 0x1
		10 0xb000 0x1
		10 0xc000 0x1
		10 0xd000 0x1
		10 0xe000 0x1
		10 0xf000 0x1
		14 0x0 0x1
		14 0x24 0x1
		14 0x48 0x1
		14 0x6c 0x1
		14 0x90 0x1
		14 0xb4 0x1
		14 0xd8 0x1
		14 0xfc 0x1
		14 0x120 0x1
		14 0x144 0x1
		14 0x168 0x1
		14 0x18c 0x1
		14 0x1b0 0x1
		14 0x1d4 0x1
		14 0x1f8 0x1
		14 0x21c 0x1
		14 0x240 0x1
		14 0x264 0x1
		14 0x288 0x1
		14 0x2ac 0x1
		14 0x2d0 0x1
		14 0x2f4 0x1
		14 0x318 0x1
		14 0x33c 0x1
		14 0x360 0x1>;
	/* Register sequences: kind, block, offset, value (see the binding) */
	/* The radio link's shutdown, through PME_Turn_Off */
	apple,radio-link-down =
		<0x0 0 0x12c 0x0>,
		<0x0 1 0x4020 0x7>,
		<0x2 1 0x104 0xf0>,
		<0x0 1 0x100 0xf0>,
		<0x7 0 0x4 0x0>,
		<0x1 0 0x18 0x0>,
		<0x0 0 0x18 0x0>,
		<0x2 1 0x800 0x100>,
		<0x0 1 0x88 0x11>,
		<0xa0005 1 0x88 0x10>,
		<0xa0006 1 0x88 0x1>,
		<0x1 1 0x208 0x0>;
	/* After the port's DART stop */
	apple,radio-link-down-port =
		<0x1 1 0x804 0x0>,
		<0x1 1 0x820 0x0>,
		<0x2 1 0x13c 0x100>,
		<0x1 0 0x728 0x0>,
		<0x1 2 0x0 0x0>,
		<0x1 1 0xa8 0x0>,
		<0x2 1 0x82c 0x1000000>,
		<0x1 2 0x0 0x0>,
		<0x1 1 0xa8 0x0>,
		<0x2 1 0x82c 0x10000>,
		<0x3 1 0x82c 0x1>,
		<0x3 1 0x82c 0x1000000>,
		<0x3 1 0x13c 0x100>,
		<0x4 2 0x0 0x0>,
		<0x3 2 0x0 0x400>,
		<0x3 2 0x0 0x200>,
		<0x2 2 0x0 0x10>,
		<0x3 2 0x0 0x1>,
		<0x3 2 0x0 0x2>,
		<0x0 1 0x100 0xffffffff>,
		<0x3 1 0x800 0x1>,
		<0x1 1 0x804 0x0>,
		<0x1 1 0x804 0x0>,
		<0x4 1 0x100 0x0>;
	/* The port's wake, after its set-up */
	apple,radio-port-wake =
		<0x0 1 0x14010 0x2>,
		<0x0 1 0x1401c 0x8>,
		<0x0 1 0x14008 0x3fff>,
		<0x0 1 0x1400c 0xffffc000>,
		<0x2 1 0x14020 0x2>,
		<0x0 1 0x14014 0x1>;
	/* After its DART's restart */
	apple,radio-dart-wake =
		<0x1 1 0x20000 0x0>,
		<0x0 1 0x20000 0xff01>,
		<0x1 1 0x20000 0x0>,
		<0x0 1 0x20000 0x8000ff01>,
		<0x0 1 0x1c000 0x10>;
	/* The shared PHY's tunables and start after a sleep */
	apple,radio-phy-wake =
		<0x640006 7 0x494 0x2>,
		<0x2 7 0x85c 0x4>,
		<0x3 6 0x0 0x4000000>,
		<0x3 4 0x0 0x10000000>,
		<0x3 4 0x4000 0x10000000>,
		<0x3 4 0x8000 0x10000000>,
		<0x3 4 0xc000 0x10000000>,
		<0xfa0105 5 0x0 0x80000000>,
		<0x2 6 0x4 0x10>,
		<0xfa0005 6 0x8 0x10>,
		<0x3 6 0x4 0x20>,
		<0xfa0005 6 0x8 0x1>,
		<0x2 5 0x0 0x1>,
		<0x2 6 0x0 0x8000000>;
	/* The shared PHY parked in the commit window */
	apple,phy-park =
		<0x3 7 0x85c 0x4>,
		<0x2 7 0x494 0x1>,
		<0x20105 7 0x494 0xb>,
		<0x2 6 0x4 0x20>,
		<0x3 6 0x4 0x10>,
		<0x1 6 0x8 0x0>,
		<0x2 7 0x828 0x20>;
	/* Before APCIE_PHY_SW goes down */
	apple,phy-down =
		<0x3 6 0x0 0x8000000>;
	/* The clusters' CPM boot writes: cluster, offset, value */
	apple,cpm-boot = /bits/ 64 <
		0 0x8000 0x0
		0 0x8008 0x0
		0 0x40f8 0x1
		1 0x8000 0x0
		1 0x8008 0x0
		1 0x40f8 0x1
		2 0x8000 0x0
		2 0x8008 0x0
		2 0x40f8 0x1
		0 0x8000 0x0
		0 0x8008 0x0
		0 0x40f8 0x1
		1 0x8000 0x0
		1 0x8008 0x0
		1 0x40f8 0x1
		2 0x8000 0x0
		2 0x8008 0x0
		2 0x40f8 0x1
		0 0x40f8 0x1
		0 0x4008 0x8b0f
		0 0x4018 0x8a0f
		0 0x4028 0xd00f
		0 0x4038 0x8c0f
		0 0x4048 0x9c0f
		0 0x4058 0x800f
		0 0x4068 0x810f
		0 0x4078 0xd50f
		0 0x4088 0xb90f
		0 0x4098 0xbe0f
		0 0x40a8 0xbf0f
		0 0x40b8 0xd40f
		1 0x40f8 0x1
		1 0x4008 0x8b0f
		1 0x4018 0x8a0f
		1 0x4028 0xd00f
		1 0x4038 0x8c0f
		1 0x4048 0x9c0f
		1 0x4058 0x800f
		1 0x4068 0x810f
		1 0x4078 0xd50f
		1 0x4088 0xb90f
		1 0x4098 0xbe0f
		1 0x40a8 0xbf0f
		1 0x40b8 0xd40f
		2 0x40f8 0x1
		2 0x4008 0x8b0f
		2 0x4018 0x8a0f
		2 0x4028 0xd00f
		2 0x4038 0x8c0f
		2 0x4048 0x9c0f
		2 0x4058 0x800f
		2 0x4068 0x810f
		2 0x4078 0xd50f
		2 0x4088 0xb90f
		2 0x4098 0xbe0f
		2 0x40a8 0xbf0f
		2 0x40b8 0xd40f
		0 0x4180 0x0
		0 0x4188 0x0
		0 0x4190 0xffffffffffffffff
		0 0x4198 0xffffffffffffffff
		0 0x41a0 0xffffffffffffffff
		0 0x41a8 0xffffffffffffffff
		0 0x41b0 0x6665
		0 0x41b8 0x0
		0 0x4180 0x3
		1 0x4180 0x0
		1 0x4188 0x0
		1 0x4190 0xffffffffffffffff
		1 0x4198 0xffffffffffffffff
		1 0x41a0 0xffffffffffffffff
		1 0x41a8 0xffffffffffffffff
		1 0x41b0 0x6665
		1 0x41b8 0x0
		1 0x4180 0x3
		2 0x4180 0x0
		2 0x4188 0x0
		2 0x4190 0xffffffffffffffff
		2 0x4198 0xffffffffffffffff
		2 0x41a0 0xffffffffffffffff
		2 0x41a8 0xffffffffffffffff
		2 0x41b0 0x6665
		2 0x41b8 0x0
		2 0x4180 0x3>;
};

&pmp0 {
	/* The PMP firmware's SRAM kept over a sleep: offset, size */
	apple,sram-keep = <0x58000 0x9b000>;
};

&pmp0_report {
	/* The PMP's memory-cache channel and PPM-TO-SMC at boot: entry, value */
	apple,ptd-boot = /bits/ 64 <
		0x245 0x600000
		0x244 0x1002
		0xfff 2
		0xffe 0x261
		0xffe 0x266
		0xffe 0x267
		0xffe 0x268
		0xffe 0x25a
		0xffe 0x25b
		0xffe 0x25c
		0xffe 0x25d
		0x270 0x0002111100000000
		0x271 0
		0x272 0
		0x273 0
		0x274 0
		0x23c 0x0004000000000000
		0x23d 0
		0x23d 0
		0x23d 0
		0x23c 0
		0x23d 0
		0x23d 0
		0x23d 0
		0x245 0
		0x244 3
		0x23c 0x400000000
		0x23c 0
		0x243 0x400000000
		0x243 0
		0xfff 3
		0x245 0
		0x244 4
		0xfff 4
		0x243 0
		0x23c 0
		0x245 0
		0x244 5
		0x23c 0
		0x23d 0
		0x23d 0
		0x23d 0
		0x23c 0x600000000
		0xfff 5
		0x245 0
		0x244 6
		0xfff 6
		0x23c 0
		0x243 0
		0x23c 0
		0x245 0
		0x244 7
		0x23c 0
		0x23d 0
		0x23d 0
		0x23d 0
		0xfff 7
		0x245 0
		0x244 8
		0xfff 8>;
};

/* Each stopped DART's GAPF slice, and the slice's live and off values */
&sep_dart {
	apple,gapf-slice = <0xb00>;
	apple,gapf-slice-values = <0x12 0x2>;
};

&pmp0_dart {
	apple,gapf-slice = <0x1c0>;
	apple,gapf-slice-values = <0x12 0x2>;
};

&sio_dart {
	apple,gapf-slice = <0xac0>;
	apple,gapf-slice-values = <0x12 0x2>;
};

&dart_apcie0 {
	apple,gapf-slice = <0x980>;
	apple,gapf-slice-values = <0x12 0x2>;
};

/*
 * The N1 over a sleep. The warm reset's writes to the key of apple,function-warm-reset (value,
 * wait after it in us), given by the host while port 0 is still down; and the N1 driver's SMC
 * writes around the sleep (key 'pcIO', the eight value bytes as two cells, wait after it in us).
 */
&port00 {
	apple,warm-reset-writes = <0x00010001 17000>, <0x00010001 20000>;
	apple,endpoint-sleep-smc-writes = <0x7063494f 0x00000000 0x00001900 0>;
	apple,endpoint-wake-smc-writes = <0x7063494f 0x01008000 0x00000e01 135000>,
					 <0x7063494f 0x01000000 0x00001900 0>;
};

/*
 * The J714s values the SIO, AOP, AOP2 and DockChannel HID drivers take from the DT, until the
 * boot loader supplies them.
 *
 * Include after t6050-j714s.dts's own includes, so that &sio is the node that
 * t6050-j714s-sleep.dtsi recreates.
 */

/* Each DMA channel's configuration words (previously sio_hw_t6050's fifo_threshold, cfg_word4) */
&sio {
	apple,channel-threshold = <0x600>;
	apple,channel-limit = <0x800>;
};

/*
 * AOP2: the INIT argument (previously AOP2_INIT_ARG), the sleep element's message words, the wake
 * element's, and the order its endpoints open in and the order they get the sleep message in
 * (previously t6050_aop2_open_order and t6050_aop2_stop_order in t6050-aop.c)
 */
&aop2 {
	apple,init-arg = <0x100>;
	apple,sleep-message = <0x0 0x4 0x2>;
	apple,wake-message = <0x0 0x4 0x4>;
	apple,open-endpoints = <0x20 0x2c 0x22 0x21 0x23 0x24>;
	apple,sleep-endpoints = <0x22 0x20 0x2c 0x21 0x23 0x24>;
};

/*
 * AOP: the order its endpoints stop in before a firmware-driven sleep, and the order they start in
 * after it (previously HW_CFG_T6050's sleep_endpoints and wake_endpoints in aop.rs)
 */
&aop {
	apple,sleep-endpoints = <0x2b 0x2c 0x21 0x2a 0x24 0x26 0x27 0x25 0x28 0x29 0x23 0x20 0x22>;
	apple,wake-endpoints = <0x22 0x28 0x27 0x23 0x21 0x20 0x29 0x24 0x2c 0x26 0x25 0x2a 0x2b>;
};

/* The feature report set on the actuator interface (index 4) before a firmware-driven sleep */
&mtp_hid {
	actuator {
		apple,sleep-report = /bits/ 8 <0x21 0x00>;
	};
};

/*
 * J714s values moved out of the DCP, DART, NVMe, PMP report and GPU drivers, until the boot
 * loader hands them over. Include after t6050-j714s.dts (it uses that tree's labels). Each value
 * is the one the code used before.
 */

/*
 * Firmware 27 display sleep RPC arguments (drivers/gpu/drm/apple/iomfb.c):
 * apple,sleep-power-args: A484 request bytes 8..15 (u32 0x01000001 LE, then u8 1, then zeros).
 * apple,sleep-a500-args: A500's 4-byte argument for the sleep (byte 1 = 1), then for the wake.
 */
&dcp {
	apple,sleep-power-args = /bits/ 8 <0x01 0x00 0x00 0x01 0x01 0x00 0x00 0x00>;
	apple,sleep-a500-args = /bits/ 8 <0x00 0x01 0x00 0x00 0x00 0x00 0x00 0x00>;
};

/*
 * The internal panel's own power state around the sleep (drivers/gpu/drm/apple/iomfb.c,
 * dcp-v27-sleep.inc) and its HDCP interface's open call (epic/panelavep.c):
 * apple,sleep-display-power-args: plain A484 request bytes 8..15, all zero.
 * apple,sleep-display-stage-args: A414's 8-byte argument (zero), then A487's 4 (u32 1 LE).
 * apple,panel-hdcp-open-arg: the fifth word of the HDCP interface's open call.
 */
&dcp {
	apple,sleep-display-power-args = /bits/ 8 <0x00 0x00 0x00 0x00 0x00 0x00 0x00 0x00>;
	apple,sleep-display-stage-args = /bits/ 8 <0x00 0x00 0x00 0x00 0x00 0x00 0x00 0x00
						   0x01 0x00 0x00 0x00>;
	apple,panel-hdcp-open-arg = <3>;
	apple,panel-video-open-delay-us = <2500>;
};

&dcpext0 {
	apple,sleep-power-args = /bits/ 8 <0x01 0x00 0x00 0x01 0x01 0x00 0x00 0x00>;
	apple,sleep-a500-args = /bits/ 8 <0x00 0x01 0x00 0x00 0x00 0x00 0x00 0x00>;
};

&dcpext1 {
	apple,sleep-power-args = /bits/ 8 <0x01 0x00 0x00 0x01 0x01 0x00 0x00 0x00>;
	apple,sleep-a500-args = /bits/ 8 <0x00 0x01 0x00 0x00 0x00 0x00 0x00 0x00>;
};

&dcpext2 {
	apple,sleep-power-args = /bits/ 8 <0x01 0x00 0x00 0x01 0x01 0x00 0x00 0x00>;
	apple,sleep-a500-args = /bits/ 8 <0x00 0x01 0x00 0x00 0x00 0x00 0x00 0x00>;
};

&dcpext3 {
	apple,sleep-power-args = /bits/ 8 <0x01 0x00 0x00 0x01 0x01 0x00 0x00 0x00>;
	apple,sleep-a500-args = /bits/ 8 <0x00 0x01 0x00 0x00 0x00 0x00 0x00 0x00>;
};

/*
 * GAPF slices of the display coprocessors' DARTs (drivers/iommu/apple-dart-v27-late.inc):
 * offset in the sleep controller's "gapf" region (0x2803f0000), then <live off> values.
 * The external display DARTs (dart_dispext0, dispext1..3_dart) have none: they are retained.
 */
&dcp_dart {		/* 0x48a340000 -> 0x2803f0a80 */
	apple,gapf-slice = <0xa80>;
	apple,gapf-slice-values = <0x12 0x2>;
};

&disp0_dart {		/* 0x48a300000 -> 0x2803f0a00 */
	apple,gapf-slice = <0xa00>;
	apple,gapf-slice-values = <0x12 0x2>;
};

&dart_dcpext0 {		/* 0x2b2340000 -> 0x2803f0500 */
	apple,gapf-slice = <0x500>;
	apple,gapf-slice-values = <0x12 0x2>;
};

&dcpext1_dart {		/* 0x392340000 -> 0x2803f0840 */
	apple,gapf-slice = <0x840>;
	apple,gapf-slice-values = <0x12 0x2>;
};

&dcpext2_dart {		/* 0x302340000 -> 0x2803f06c0 */
	apple,gapf-slice = <0x6c0>;
	apple,gapf-slice-values = <0x12 0x2>;
};

&dcpext3_dart {		/* 0x306340000 -> 0x2803f0780 */
	apple,gapf-slice = <0x780>;
	apple,gapf-slice-values = <0x12 0x2>;
};

/* ANS2: the wait from the storage power being back to the co-processor restart (apple-m5-sleep.h) */
&nvme {
	apple,sleep-wake-delay-ms = <70>;
};

/* PMP report: the PTD entry the memory-cache channel echoes into (apple,ptd-boot's 0xfff steps) */
&pmp0_report {
	apple,ptd-echo-entry = <0x269>;
};

/*
 * GPU: the PS automatic state (bits 27:24) its domain is raised with after a sleep, and the floor
 * (bits 19:16) the boot leaves in its word (0x1404034f), which the wake's replay clears
 * (g17/sleep.c)
 */
&sgx {
	apple,sleep-ps-auto = <0xf>;
	apple,sleep-ps-min = <4>;
};

/*
 * TEST: the right port's USB4 router sleeping in place, with its tunnels kept, as macOS has
 * it (run mxt4; drivers/thunderbolt/apple-cio-sleep.c). The clock protection slices of the
 * NHI's and the tunnelled PCIe's DART are words 0x880 and 0x8c0 of the block the sleep
 * controller knows as "gapf": macOS writes each to its off value (bit 4 clear) right after
 * taking that DART down and back to the live value before using it again. The router's host
 * also needs the port's PHY, which it stops after the router and starts before it. The left
 * port's router was never up in a trace: it has none of this and is powered off for a sleep.
 */
&die0 {
	ps_prot: syscon@2803f0000 {
		compatible = "apple,t6050-ps-prot", "syscon";
		reg = <0x2 0x803f0000 0x0 0x4000>;
	};
};

&acio2 {
	apple,cio-phy = <&atc2_phy>;
};

&acio2_dart {
	apple,clock-protection = <&ps_prot 30>;
};

&apciec2_dart {
	apple,clock-protection = <&ps_prot 31>;
};
